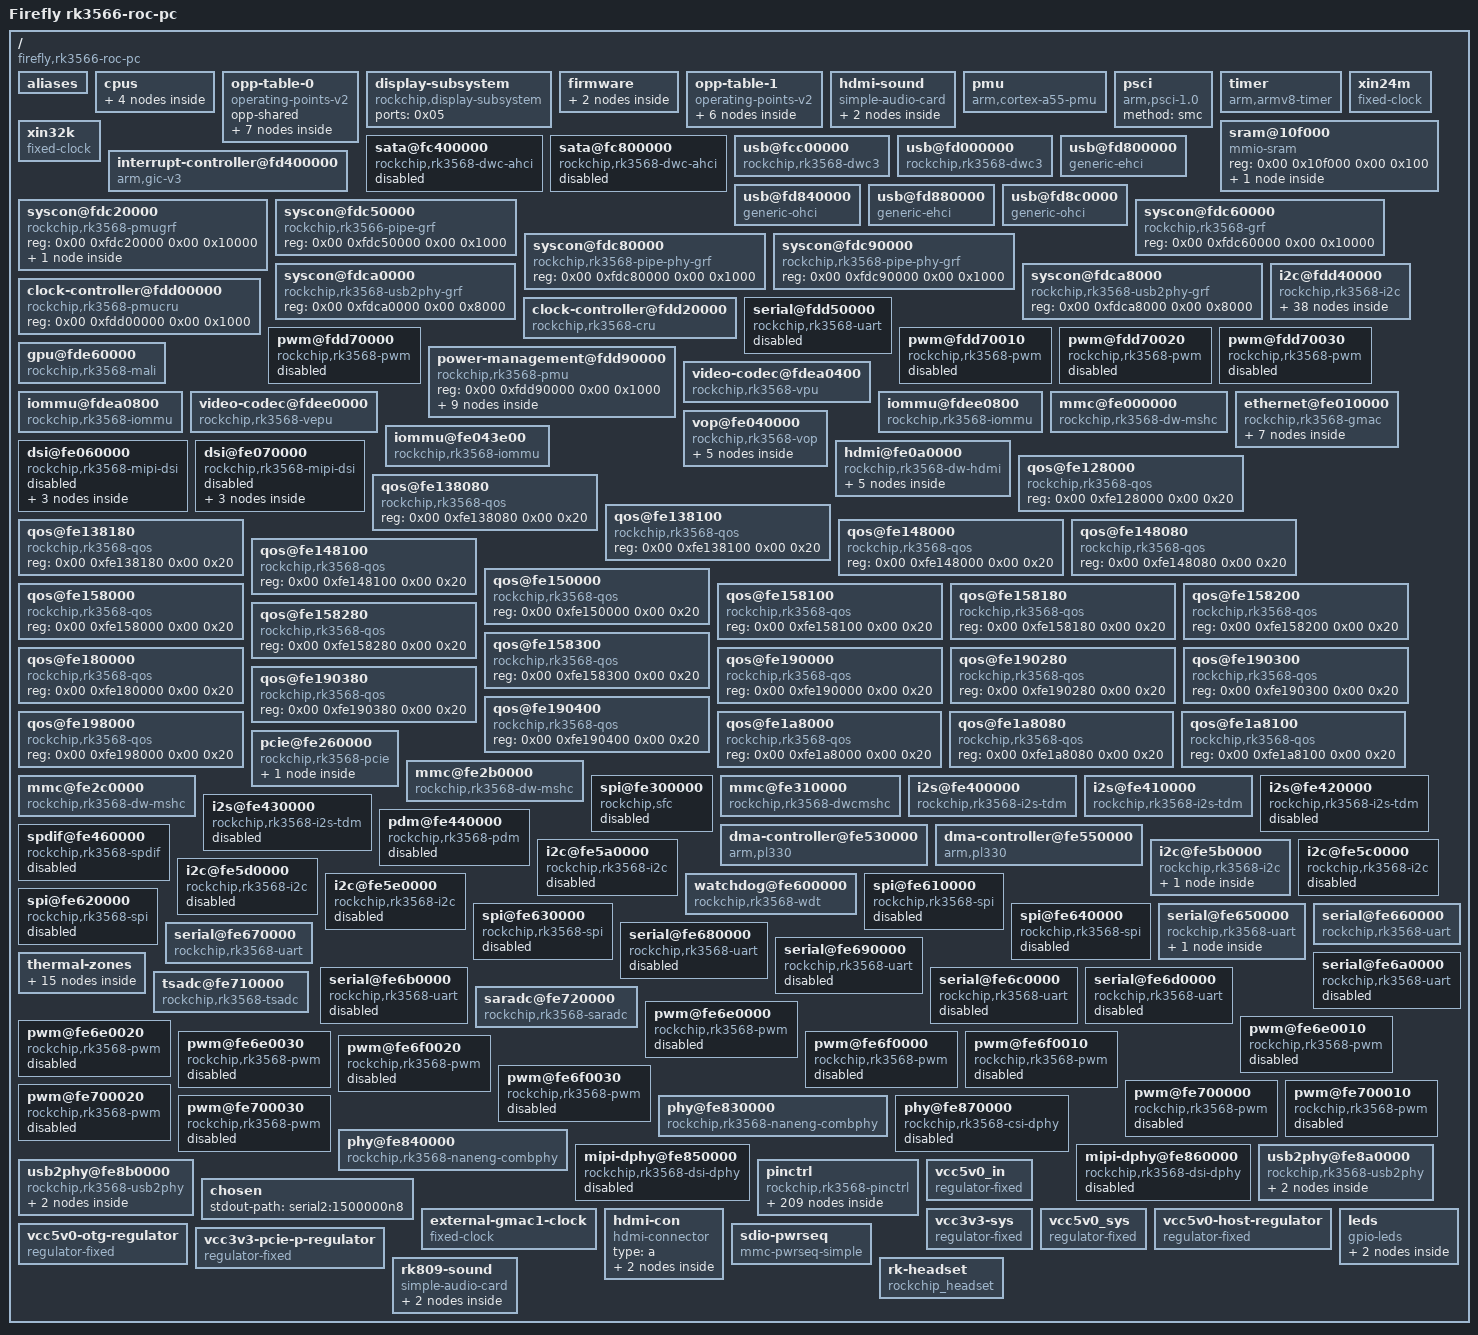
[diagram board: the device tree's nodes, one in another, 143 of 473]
/dts-v1/;

/ {
	interrupt-parent = <0x01>;
	#address-cells = <0x02>;
	#size-cells = <0x02>;
	compatible = "firefly,rk3566-roc-pc\0rockchip,rk3566";
	model = "Firefly rk3566-roc-pc";

	aliases {
		gpio0 = "/pinctrl/gpio@fdd60000";
		gpio1 = "/pinctrl/gpio@fe740000";
		gpio2 = "/pinctrl/gpio@fe750000";
		gpio3 = "/pinctrl/gpio@fe760000";
		gpio4 = "/pinctrl/gpio@fe770000";
		i2c0 = "/i2c@fdd40000";
		i2c1 = "/i2c@fe5a0000";
		i2c2 = "/i2c@fe5b0000";
		i2c3 = "/i2c@fe5c0000";
		i2c4 = "/i2c@fe5d0000";
		i2c5 = "/i2c@fe5e0000";
		serial0 = "/serial@fdd50000";
		serial1 = "/serial@fe650000";
		serial2 = "/serial@fe660000";
		serial3 = "/serial@fe670000";
		serial4 = "/serial@fe680000";
		serial5 = "/serial@fe690000";
		serial6 = "/serial@fe6a0000";
		serial7 = "/serial@fe6b0000";
		serial8 = "/serial@fe6c0000";
		serial9 = "/serial@fe6d0000";
		spi0 = "/spi@fe610000";
		spi1 = "/spi@fe620000";
		spi2 = "/spi@fe630000";
		spi3 = "/spi@fe640000";
		ethernet0 = "/ethernet@fe010000";
		mmc0 = "/mmc@fe2b0000";
		mmc1 = "/mmc@fe310000";
		mmc2 = "/mmc@fe2c0000";
	};

	cpus {
		#address-cells = <0x02>;
		#size-cells = <0x00>;

		cpu@0 {
			device_type = "cpu";
			compatible = "arm,cortex-a55";
			reg = <0x00 0x00>;
			clocks = <0x02 0x00>;
			#cooling-cells = <0x02>;
			enable-method = "psci";
			operating-points-v2 = <0x03>;
			cpu-supply = <0x04>;
			phandle = <0x09>;
		};

		cpu@100 {
			device_type = "cpu";
			compatible = "arm,cortex-a55";
			reg = <0x00 0x100>;
			#cooling-cells = <0x02>;
			enable-method = "psci";
			operating-points-v2 = <0x03>;
			cpu-supply = <0x04>;
			phandle = <0x0a>;
		};

		cpu@200 {
			device_type = "cpu";
			compatible = "arm,cortex-a55";
			reg = <0x00 0x200>;
			#cooling-cells = <0x02>;
			enable-method = "psci";
			operating-points-v2 = <0x03>;
			cpu-supply = <0x04>;
			phandle = <0x0b>;
		};

		cpu@300 {
			device_type = "cpu";
			compatible = "arm,cortex-a55";
			reg = <0x00 0x300>;
			#cooling-cells = <0x02>;
			enable-method = "psci";
			operating-points-v2 = <0x03>;
			cpu-supply = <0x04>;
			phandle = <0x0c>;
		};
	};

	opp-table-0 {
		compatible = "operating-points-v2";
		opp-shared;
		phandle = <0x03>;

		opp-408000000 {
			opp-hz = <0x00 0x18519600>;
			opp-microvolt = <0xdbba0 0xdbba0 0x118c30>;
			clock-latency-ns = <0x9c40>;
		};

		opp-600000000 {
			opp-hz = <0x00 0x23c34600>;
			opp-microvolt = <0xdbba0 0xdbba0 0x118c30>;
		};

		opp-816000000 {
			opp-hz = <0x00 0x30a32c00>;
			opp-microvolt = <0xdbba0 0xdbba0 0x118c30>;
			opp-suspend;
		};

		opp-1104000000 {
			opp-hz = <0x00 0x41cdb400>;
			opp-microvolt = <0xdbba0 0xdbba0 0x118c30>;
		};

		opp-1416000000 {
			opp-hz = <0x00 0x54667200>;
			opp-microvolt = <0xdbba0 0xdbba0 0x118c30>;
		};

		opp-1608000000 {
			opp-hz = <0x00 0x5fd82200>;
			opp-microvolt = <0xee098 0xee098 0x118c30>;
		};

		opp-1800000000 {
			opp-hz = <0x00 0x6b49d200>;
			opp-microvolt = <0x100590 0x100590 0x118c30>;
		};
	};

	display-subsystem {
		compatible = "rockchip,display-subsystem";
		ports = <0x05>;
	};

	firmware {

		scmi {
			compatible = "arm,scmi-smc";
			arm,smc-id = <0x82000010>;
			shmem = <0x06>;
			#address-cells = <0x01>;
			#size-cells = <0x00>;

			protocol@14 {
				reg = <0x14>;
				#clock-cells = <0x01>;
				phandle = <0x02>;
			};
		};
	};

	opp-table-1 {
		compatible = "operating-points-v2";
		phandle = <0x42>;

		opp-200000000 {
			opp-hz = <0x00 0xbebc200>;
			opp-microvolt = <0xc96a8>;
		};

		opp-300000000 {
			opp-hz = <0x00 0x11e1a300>;
			opp-microvolt = <0xc96a8>;
		};

		opp-400000000 {
			opp-hz = <0x00 0x17d78400>;
			opp-microvolt = <0xc96a8>;
		};

		opp-600000000 {
			opp-hz = <0x00 0x23c34600>;
			opp-microvolt = <0xc96a8>;
		};

		opp-700000000 {
			opp-hz = <0x00 0x29b92700>;
			opp-microvolt = <0xdbba0>;
		};

		opp-800000000 {
			opp-hz = <0x00 0x2faf0800>;
			opp-microvolt = <0xf4240>;
		};
	};

	hdmi-sound {
		compatible = "simple-audio-card";
		simple-audio-card,name = "HDMI";
		simple-audio-card,format = "i2s";
		simple-audio-card,mclk-fs = <0x100>;
		status = "okay";

		simple-audio-card,codec {
			sound-dai = <0x07>;
		};

		simple-audio-card,cpu {
			sound-dai = <0x08>;
		};
	};

	pmu {
		compatible = "arm,cortex-a55-pmu";
		interrupts = <0x00 0xe4 0x04 0x00 0xe5 0x04 0x00 0xe6 0x04 0x00 0xe7 0x04>;
		interrupt-affinity = <0x09 0x0a 0x0b 0x0c>;
	};

	psci {
		compatible = "arm,psci-1.0";
		method = "smc";
	};

	timer {
		compatible = "arm,armv8-timer";
		interrupts = <0x01 0x0d 0x04 0x01 0x0e 0x04 0x01 0x0b 0x04 0x01 0x0a 0x04>;
		arm,no-tick-in-suspend;
	};

	xin24m {
		compatible = "fixed-clock";
		clock-frequency = <0x16e3600>;
		clock-output-names = "xin24m";
		#clock-cells = <0x00>;
		phandle = <0x1c>;
	};

	xin32k {
		compatible = "fixed-clock";
		clock-frequency = <0x8000>;
		clock-output-names = "xin32k";
		pinctrl-0 = <0x0d>;
		pinctrl-names = "default";
		#clock-cells = <0x00>;
	};

	sram@10f000 {
		compatible = "mmio-sram";
		reg = <0x00 0x10f000 0x00 0x100>;
		#address-cells = <0x01>;
		#size-cells = <0x01>;
		ranges = <0x00 0x00 0x10f000 0x100>;

		sram@0 {
			compatible = "arm,scmi-shmem";
			reg = <0x00 0x100>;
			phandle = <0x06>;
		};
	};

	sata@fc400000 {
		compatible = "rockchip,rk3568-dwc-ahci\0snps,dwc-ahci";
		reg = <0x00 0xfc400000 0x00 0x1000>;
		clocks = <0x0e 0x9b 0x0e 0x9c 0x0e 0x9d>;
		clock-names = "sata\0pmalive\0rxoob";
		interrupts = <0x00 0x5f 0x04>;
		phys = <0x0f 0x01>;
		phy-names = "sata-phy";
		ports-implemented = <0x01>;
		power-domains = <0x10 0x0f>;
		status = "disabled";
	};

	sata@fc800000 {
		compatible = "rockchip,rk3568-dwc-ahci\0snps,dwc-ahci";
		reg = <0x00 0xfc800000 0x00 0x1000>;
		clocks = <0x0e 0xa0 0x0e 0xa1 0x0e 0xa2>;
		clock-names = "sata\0pmalive\0rxoob";
		interrupts = <0x00 0x60 0x04>;
		phys = <0x11 0x01>;
		phy-names = "sata-phy";
		ports-implemented = <0x01>;
		power-domains = <0x10 0x0f>;
		status = "disabled";
	};

	usb@fcc00000 {
		compatible = "rockchip,rk3568-dwc3\0snps,dwc3";
		reg = <0x00 0xfcc00000 0x00 0x400000>;
		interrupts = <0x00 0xa9 0x04>;
		clocks = <0x0e 0xa6 0x0e 0xa7 0x0e 0xa5>;
		clock-names = "ref_clk\0suspend_clk\0bus_clk";
		dr_mode = "host";
		phy_type = "utmi_wide";
		power-domains = <0x10 0x0f>;
		resets = <0x0e 0x94>;
		snps,dis_u2_susphy_quirk;
		status = "okay";
		phys = <0x12>;
		phy-names = "usb2-phy";
		extcon = <0x13>;
		maximum-speed = "high-speed";
	};

	usb@fd000000 {
		compatible = "rockchip,rk3568-dwc3\0snps,dwc3";
		reg = <0x00 0xfd000000 0x00 0x400000>;
		interrupts = <0x00 0xaa 0x04>;
		clocks = <0x0e 0xa9 0x0e 0xaa 0x0e 0xa8>;
		clock-names = "ref_clk\0suspend_clk\0bus_clk";
		dr_mode = "host";
		phys = <0x14 0x0f 0x04>;
		phy-names = "usb2-phy\0usb3-phy";
		phy_type = "utmi_wide";
		power-domains = <0x10 0x0f>;
		resets = <0x0e 0x95>;
		snps,dis_u2_susphy_quirk;
		status = "okay";
	};

	interrupt-controller@fd400000 {
		compatible = "arm,gic-v3";
		reg = <0x00 0xfd400000 0x00 0x10000 0x00 0xfd460000 0x00 0x80000>;
		interrupts = <0x01 0x09 0x04>;
		interrupt-controller;
		#interrupt-cells = <0x03>;
		mbi-alias = <0x00 0xfd410000>;
		mbi-ranges = <0x128 0x18>;
		msi-controller;
		phandle = <0x01>;
	};

	usb@fd800000 {
		compatible = "generic-ehci";
		reg = <0x00 0xfd800000 0x00 0x40000>;
		interrupts = <0x00 0x82 0x04>;
		clocks = <0x0e 0xbd 0x0e 0xbe 0x0e 0xbc>;
		phys = <0x15>;
		phy-names = "usb";
		status = "okay";
	};

	usb@fd840000 {
		compatible = "generic-ohci";
		reg = <0x00 0xfd840000 0x00 0x40000>;
		interrupts = <0x00 0x83 0x04>;
		clocks = <0x0e 0xbd 0x0e 0xbe 0x0e 0xbc>;
		phys = <0x15>;
		phy-names = "usb";
		status = "okay";
	};

	usb@fd880000 {
		compatible = "generic-ehci";
		reg = <0x00 0xfd880000 0x00 0x40000>;
		interrupts = <0x00 0x85 0x04>;
		clocks = <0x0e 0xbf 0x0e 0xc0 0x0e 0xbc>;
		phys = <0x16>;
		phy-names = "usb";
		status = "okay";
	};

	usb@fd8c0000 {
		compatible = "generic-ohci";
		reg = <0x00 0xfd8c0000 0x00 0x40000>;
		interrupts = <0x00 0x86 0x04>;
		clocks = <0x0e 0xbf 0x0e 0xc0 0x0e 0xbc>;
		phys = <0x16>;
		phy-names = "usb";
		status = "okay";
	};

	syscon@fdc20000 {
		compatible = "rockchip,rk3568-pmugrf\0syscon\0simple-mfd";
		reg = <0x00 0xfdc20000 0x00 0x10000>;
		phandle = <0xbb>;

		io-domains {
			compatible = "rockchip,rk3568-pmu-io-voltage-domain";
			status = "okay";
			pmuio1-supply = <0x17>;
			pmuio2-supply = <0x17>;
			vccio1-supply = <0x18>;
			vccio2-supply = <0x19>;
			vccio3-supply = <0x1a>;
			vccio4-supply = <0x19>;
			vccio5-supply = <0x1b>;
			vccio6-supply = <0x19>;
			vccio7-supply = <0x1b>;
		};
	};

	syscon@fdc50000 {
		reg = <0x00 0xfdc50000 0x00 0x1000>;
		compatible = "rockchip,rk3566-pipe-grf\0syscon";
		phandle = <0xb4>;
	};

	syscon@fdc60000 {
		compatible = "rockchip,rk3568-grf\0syscon\0simple-mfd";
		reg = <0x00 0xfdc60000 0x00 0x10000>;
		phandle = <0x1e>;
	};

	syscon@fdc80000 {
		compatible = "rockchip,rk3568-pipe-phy-grf\0syscon";
		reg = <0x00 0xfdc80000 0x00 0x1000>;
		phandle = <0xb5>;
	};

	syscon@fdc90000 {
		compatible = "rockchip,rk3568-pipe-phy-grf\0syscon";
		reg = <0x00 0xfdc90000 0x00 0x1000>;
		phandle = <0xb6>;
	};

	syscon@fdca0000 {
		compatible = "rockchip,rk3568-usb2phy-grf\0syscon";
		reg = <0x00 0xfdca0000 0x00 0x8000>;
		phandle = <0xb7>;
	};

	syscon@fdca8000 {
		compatible = "rockchip,rk3568-usb2phy-grf\0syscon";
		reg = <0x00 0xfdca8000 0x00 0x8000>;
		phandle = <0xba>;
	};

	clock-controller@fdd00000 {
		compatible = "rockchip,rk3568-pmucru";
		reg = <0x00 0xfdd00000 0x00 0x1000>;
		#clock-cells = <0x01>;
		#reset-cells = <0x01>;
		phandle = <0x1d>;
	};

	clock-controller@fdd20000 {
		compatible = "rockchip,rk3568-cru";
		reg = <0x00 0xfdd20000 0x00 0x1000>;
		clocks = <0x1c>;
		clock-names = "xin24m";
		#clock-cells = <0x01>;
		#reset-cells = <0x01>;
		assigned-clocks = <0x1d 0x05 0x0e 0x04 0x1d 0x01>;
		assigned-clock-rates = <0x8000 0x47868c00 0xbebc200>;
		assigned-clock-parents = <0x1d 0x08>;
		rockchip,grf = <0x1e>;
		phandle = <0x0e>;
	};

	i2c@fdd40000 {
		compatible = "rockchip,rk3568-i2c\0rockchip,rk3399-i2c";
		reg = <0x00 0xfdd40000 0x00 0x1000>;
		interrupts = <0x00 0x2e 0x04>;
		clocks = <0x1d 0x07 0x1d 0x2d>;
		clock-names = "i2c\0pclk";
		pinctrl-0 = <0x1f>;
		pinctrl-names = "default";
		#address-cells = <0x01>;
		#size-cells = <0x00>;
		status = "okay";

		regulator@1c {
			compatible = "tcs,tcs4525";
			reg = <0x1c>;
			vin-supply = <0x20>;
			regulator-name = "vdd_cpu";
			regulator-min-microvolt = "\0\f5";
			regulator-max-microvolt = <0x118c30>;
			regulator-ramp-delay = <0x8fc>;
			fcs,suspend-voltage-selector = <0x01>;
			regulator-boot-on;
			regulator-always-on;
			phandle = <0x04>;

			regulator-state-mem {
				regulator-off-in-suspend;
			};
		};

		pmic@20 {
			compatible = "rockchip,rk809";
			reg = <0x20>;
			interrupt-parent = <0x21>;
			interrupts = <0x07 0x08>;
			clock-output-names = "rk808-clkout1\0rk808-clkout2";
			assigned-clocks = <0x0e 0x48>;
			assigned-clock-parents = <0x0e 0x196>;
			clock-names = "mclk";
			clocks = <0x0e 0x48>;
			pinctrl-names = "default";
			pinctrl-0 = <0x22 0x23>;
			rockchip,system-power-controller;
			wakeup-source;
			#clock-cells = <0x01>;
			#sound-dai-cells = <0x00>;
			vcc1-supply = <0x24>;
			vcc2-supply = <0x24>;
			vcc3-supply = <0x24>;
			vcc4-supply = <0x24>;
			vcc5-supply = <0x24>;
			vcc6-supply = <0x24>;
			vcc7-supply = <0x24>;
			vcc8-supply = <0x24>;
			vcc9-supply = <0x24>;
			phandle = <0x94>;

			regulators {

				DCDC_REG1 {
					regulator-name = "vdd_logic";
					regulator-always-on;
					regulator-boot-on;
					regulator-init-microvolt = <0xdbba0>;
					regulator-initial-mode = <0x02>;
					regulator-min-microvolt = <0x7a120>;
					regulator-max-microvolt = <0x149970>;
					regulator-ramp-delay = <0x1771>;

					regulator-state-mem {
						regulator-off-in-suspend;
					};
				};

				DCDC_REG2 {
					regulator-always-on;
					regulator-boot-on;
					regulator-name = "vdd_gpu";
					regulator-init-microvolt = <0xdbba0>;
					regulator-initial-mode = <0x02>;
					regulator-min-microvolt = <0x7a120>;
					regulator-max-microvolt = <0x149970>;
					regulator-ramp-delay = <0x1771>;
					phandle = <0x43>;

					regulator-state-mem {
						regulator-off-in-suspend;
					};
				};

				DCDC_REG3 {
					regulator-name = "vcc_ddr";
					regulator-always-on;
					regulator-boot-on;
					regulator-initial-mode = <0x02>;

					regulator-state-mem {
						regulator-on-in-suspend;
					};
				};

				DCDC_REG4 {
					regulator-name = "vdd_npu";
					regulator-init-microvolt = <0xdbba0>;
					regulator-initial-mode = <0x02>;
					regulator-min-microvolt = <0x7a120>;
					regulator-max-microvolt = <0x149970>;
					regulator-ramp-delay = <0x1771>;

					regulator-state-mem {
						regulator-off-in-suspend;
					};
				};

				LDO_REG1 {
					regulator-boot-on;
					regulator-always-on;
					regulator-name = "vdda0v9_image";
					regulator-min-microvolt = <0xdbba0>;
					regulator-max-microvolt = <0xdbba0>;
					phandle = <0x5c>;

					regulator-state-mem {
						regulator-off-in-suspend;
					};
				};

				LDO_REG2 {
					regulator-name = "vdda_0v9";
					regulator-always-on;
					regulator-boot-on;
					regulator-min-microvolt = <0xdbba0>;
					regulator-max-microvolt = <0xdbba0>;

					regulator-state-mem {
						regulator-off-in-suspend;
					};
				};

				LDO_REG3 {
					regulator-name = "vdda0v9_pmu";
					regulator-always-on;
					regulator-boot-on;
					regulator-min-microvolt = <0xdbba0>;
					regulator-max-microvolt = <0xdbba0>;

					regulator-state-mem {
						regulator-on-in-suspend;
						regulator-suspend-microvolt = <0xdbba0>;
					};
				};

				LDO_REG4 {
					regulator-always-on;
					regulator-boot-on;
					regulator-name = "vccio_acodec";
					regulator-min-microvolt = <0x325aa0>;
					regulator-max-microvolt = <0x325aa0>;
					phandle = <0x18>;

					regulator-state-mem {
						regulator-off-in-suspend;
					};
				};

				LDO_REG5 {
					regulator-name = "vccio_sd";
					regulator-always-on;
					regulator-boot-on;
					regulator-min-microvolt = <0x1b7740>;
					regulator-max-microvolt = <0x325aa0>;
					phandle = <0x1a>;

					regulator-state-mem {
						regulator-off-in-suspend;
					};
				};

				LDO_REG6 {
					regulator-name = "vcc3v3_pmu";
					regulator-always-on;
					regulator-boot-on;
					regulator-min-microvolt = <0x325aa0>;
					regulator-max-microvolt = <0x325aa0>;
					phandle = <0x17>;

					regulator-state-mem {
						regulator-on-in-suspend;
						regulator-suspend-microvolt = <0x325aa0>;
					};
				};

				LDO_REG7 {
					regulator-name = "vcca_1v8";
					regulator-always-on;
					regulator-boot-on;
					regulator-min-microvolt = <0x1b7740>;
					regulator-max-microvolt = <0x1b7740>;
					phandle = <0xa7>;

					regulator-state-mem {
						regulator-off-in-suspend;
					};
				};

				LDO_REG8 {
					regulator-name = "vcca1v8_pmu";
					regulator-always-on;
					regulator-boot-on;
					regulator-min-microvolt = <0x1b7740>;
					regulator-max-microvolt = <0x1b7740>;
					phandle = <0x46>;

					regulator-state-mem {
						regulator-on-in-suspend;
						regulator-suspend-microvolt = <0x1b7740>;
					};
				};

				LDO_REG9 {
					regulator-name = "vcca1v8_image";
					regulator-min-microvolt = <0x1b7740>;
					regulator-max-microvolt = <0x1b7740>;
					phandle = <0x5d>;

					regulator-state-mem {
						regulator-off-in-suspend;
					};
				};

				DCDC_REG5 {
					regulator-always-on;
					regulator-boot-on;
					regulator-min-microvolt = <0x1b7740>;
					regulator-max-microvolt = <0x1b7740>;
					regulator-name = "vcc_1v8";
					phandle = <0x19>;

					regulator-state-mem {
						regulator-off-in-suspend;
					};
				};

				SWITCH_REG1 {
					regulator-name = "vcc_3v3";
					regulator-always-on;
					regulator-boot-on;
					phandle = <0x1b>;

					regulator-state-mem {
						regulator-off-in-suspend;
					};
				};

				SWITCH_REG2 {
					regulator-name = "vcc3v3_sd";
					regulator-always-on;
					regulator-boot-on;
					phandle = <0x68>;

					regulator-state-mem {
						regulator-off-in-suspend;
					};
				};
			};

			rtc {
				status = "disabled";
			};

			codec {
				mic-in-differential;
			};
		};
	};

	serial@fdd50000 {
		compatible = "rockchip,rk3568-uart\0snps,dw-apb-uart";
		reg = <0x00 0xfdd50000 0x00 0x100>;
		interrupts = <0x00 0x74 0x04>;
		clocks = <0x1d 0x0b 0x1d 0x2c>;
		clock-names = "baudclk\0apb_pclk";
		dmas = <0x25 0x00 0x25 0x01>;
		pinctrl-0 = <0x26>;
		pinctrl-names = "default";
		reg-io-width = <0x04>;
		reg-shift = <0x02>;
		status = "disabled";
	};

	pwm@fdd70000 {
		compatible = "rockchip,rk3568-pwm\0rockchip,rk3328-pwm";
		reg = <0x00 0xfdd70000 0x00 0x10>;
		clocks = <0x1d 0x0d 0x1d 0x30>;
		clock-names = "pwm\0pclk";
		pinctrl-0 = <0x27>;
		pinctrl-names = "default";
		#pwm-cells = <0x03>;
		status = "disabled";
	};

	pwm@fdd70010 {
		compatible = "rockchip,rk3568-pwm\0rockchip,rk3328-pwm";
		reg = <0x00 0xfdd70010 0x00 0x10>;
		clocks = <0x1d 0x0d 0x1d 0x30>;
		clock-names = "pwm\0pclk";
		pinctrl-0 = <0x28>;
		pinctrl-names = "default";
		#pwm-cells = <0x03>;
		status = "disabled";
	};

	pwm@fdd70020 {
		compatible = "rockchip,rk3568-pwm\0rockchip,rk3328-pwm";
		reg = <0x00 0xfdd70020 0x00 0x10>;
		clocks = <0x1d 0x0d 0x1d 0x30>;
		clock-names = "pwm\0pclk";
		pinctrl-0 = <0x29>;
		pinctrl-names = "default";
		#pwm-cells = <0x03>;
		status = "disabled";
	};

	pwm@fdd70030 {
		compatible = "rockchip,rk3568-pwm\0rockchip,rk3328-pwm";
		reg = <0x00 0xfdd70030 0x00 0x10>;
		clocks = <0x1d 0x0d 0x1d 0x30>;
		clock-names = "pwm\0pclk";
		pinctrl-0 = <0x2a>;
		pinctrl-names = "default";
		#pwm-cells = <0x03>;
		status = "disabled";
	};

	power-management@fdd90000 {
		compatible = "rockchip,rk3568-pmu\0syscon\0simple-mfd";
		reg = <0x00 0xfdd90000 0x00 0x1000>;

		power-controller {
			compatible = "rockchip,rk3568-power-controller";
			#power-domain-cells = <0x01>;
			#address-cells = <0x01>;
			#size-cells = <0x00>;
			phandle = <0x10>;

			power-domain@7 {
				reg = <0x07>;
				clocks = <0x0e 0x19 0x0e 0x1a>;
				pm_qos = <0x2b>;
				#power-domain-cells = <0x00>;
			};

			power-domain@8 {
				reg = <0x08>;
				clocks = <0x0e 0xcc 0x0e 0xcd>;
				pm_qos = <0x2c 0x2d 0x2e>;
				#power-domain-cells = <0x00>;
			};

			power-domain@9 {
				reg = <0x09>;
				clocks = <0x0e 0xda 0x0e 0xdb 0x0e 0xdc>;
				pm_qos = <0x2f 0x30 0x31>;
				#power-domain-cells = <0x00>;
			};

			power-domain@10 {
				reg = <0x0a>;
				clocks = <0x0e 0xf1 0x0e 0xf2>;
				pm_qos = <0x32 0x33 0x34 0x35 0x36 0x37>;
				#power-domain-cells = <0x00>;
			};

			power-domain@11 {
				reg = <0x0b>;
				clocks = <0x0e 0xed>;
				pm_qos = <0x38>;
				#power-domain-cells = <0x00>;
			};

			power-domain@13 {
				clocks = <0x0e 0x107>;
				reg = <0x0d>;
				pm_qos = <0x39>;
				#power-domain-cells = <0x00>;
			};

			power-domain@14 {
				reg = <0x0e>;
				clocks = <0x0e 0x102>;
				pm_qos = <0x3a 0x3b 0x3c>;
				#power-domain-cells = <0x00>;
			};

			power-domain@15 {
				reg = <0x0f>;
				clocks = <0x0e 0x7f>;
				pm_qos = <0x3d 0x3e 0x3f 0x40 0x41>;
				#power-domain-cells = <0x00>;
			};
		};
	};

	gpu@fde60000 {
		compatible = "rockchip,rk3568-mali\0arm,mali-bifrost";
		reg = <0x00 0xfde60000 0x00 0x4000>;
		interrupts = <0x00 0x28 0x04 0x00 0x29 0x04 0x00 0x27 0x04>;
		interrupt-names = "job\0mmu\0gpu";
		clocks = <0x02 0x01 0x0e 0x1b>;
		clock-names = "gpu\0bus";
		#cooling-cells = <0x02>;
		operating-points-v2 = <0x42>;
		power-domains = <0x10 0x07>;
		status = "okay";
		mali-supply = <0x43>;
		phandle = <0xa4>;
	};

	video-codec@fdea0400 {
		compatible = "rockchip,rk3568-vpu";
		reg = <0x00 0xfdea0000 0x00 0x800>;
		interrupts = <0x00 0x8b 0x04>;
		clocks = <0x0e 0xee 0x0e 0xef>;
		clock-names = "aclk\0hclk";
		iommus = <0x44>;
		power-domains = <0x10 0x0b>;
	};

	iommu@fdea0800 {
		compatible = "rockchip,rk3568-iommu";
		reg = <0x00 0xfdea0800 0x00 0x40>;
		interrupts = <0x00 0x8a 0x04>;
		clock-names = "aclk\0iface";
		clocks = <0x0e 0xee 0x0e 0xef>;
		power-domains = <0x10 0x0b>;
		#iommu-cells = <0x00>;
		phandle = <0x44>;
	};

	video-codec@fdee0000 {
		compatible = "rockchip,rk3568-vepu";
		reg = <0x00 0xfdee0000 0x00 0x800>;
		interrupts = <0x00 0x40 0x04>;
		clocks = <0x0e 0xfd 0x0e 0xfe>;
		clock-names = "aclk\0hclk";
		iommus = <0x45>;
		power-domains = <0x10 0x0a>;
	};

	iommu@fdee0800 {
		compatible = "rockchip,rk3568-iommu";
		reg = <0x00 0xfdee0800 0x00 0x40>;
		interrupts = <0x00 0x3f 0x04>;
		clocks = <0x0e 0xfd 0x0e 0xfe>;
		clock-names = "aclk\0iface";
		power-domains = <0x10 0x0a>;
		#iommu-cells = <0x00>;
		phandle = <0x45>;
	};

	mmc@fe000000 {
		compatible = "rockchip,rk3568-dw-mshc\0rockchip,rk3288-dw-mshc";
		reg = <0x00 0xfe000000 0x00 0x4000>;
		interrupts = <0x00 0x64 0x04>;
		clocks = <0x0e 0xc1 0x0e 0xc2 0x0e 0x18e 0x0e 0x18f>;
		clock-names = "biu\0ciu\0ciu-drive\0ciu-sample";
		fifo-depth = <0x100>;
		max-frequency = <0x8f0d180>;
		resets = <0x0e 0xeb>;
		reset-names = "reset";
		status = "okay";
		cap-sd-highspeed;
		cap-sdio-irq;
		bus-width = <0x04>;
		vmmc-supply = <0x1b>;
		vqmmc-supply = <0x46>;
		pinctrl-names = "default";
		pinctrl-0 = <0x47 0x48 0x49>;
		sd-uhs-sdr104;
	};

	ethernet@fe010000 {
		compatible = "rockchip,rk3568-gmac\0snps,dwmac-4.20a";
		reg = <0x00 0xfe010000 0x00 0x10000>;
		interrupts = <0x00 0x20 0x04 0x00 0x1d 0x04>;
		interrupt-names = "macirq\0eth_wake_irq";
		clocks = <0x0e 0x186 0x0e 0x189 0x0e 0x189 0x0e 0xc7 0x0e 0xc3 0x0e 0xc4 0x0e 0x189 0x0e 0xc8>;
		clock-names = "stmmaceth\0mac_clk_rx\0mac_clk_tx\0clk_mac_refout\0aclk_mac\0pclk_mac\0clk_mac_speed\0ptp_ref";
		resets = <0x0e 0xec>;
		reset-names = "stmmaceth";
		rockchip,grf = <0x1e>;
		snps,axi-config = <0x4a>;
		snps,mixed-burst;
		snps,mtl-rx-config = <0x4b>;
		snps,mtl-tx-config = <0x4c>;
		snps,tso;
		status = "okay";
		assigned-clocks = <0x0e 0x189 0x0e 0x187 0x0e 0x186>;
		assigned-clock-parents = <0x0e 0x187 0x0e 0x186 0x4d>;
		clock_in_out = "input";
		phy-supply = <0x1b>;
		phy-mode = "rgmii";
		pinctrl-names = "default";
		pinctrl-0 = <0x4e 0x4f 0x50 0x51 0x52 0x53>;
		snps,reset-gpio = <0x21 0x0f 0x01>;
		snps,reset-active-low;
		snps,reset-delays-us = <0x00 0x4e20 0x186a0>;
		tx_delay = <0x4e>;
		rx_delay = <0x2c>;
		phy-handle = <0x54>;

		mdio {
			compatible = "snps,dwmac-mdio";
			#address-cells = <0x01>;
			#size-cells = <0x00>;

			ethernet-phy@0 {
				compatible = "ethernet-phy-ieee802.3-c22";
				reg = <0x00>;
				phandle = <0x54>;
			};
		};

		stmmac-axi-config {
			snps,blen = <0x00 0x00 0x00 0x00 0x10 0x08 0x04>;
			snps,rd_osr_lmt = <0x08>;
			snps,wr_osr_lmt = <0x04>;
			phandle = <0x4a>;
		};

		rx-queues-config {
			snps,rx-queues-to-use = <0x01>;
			phandle = <0x4b>;

			queue0 {
			};
		};

		tx-queues-config {
			snps,tx-queues-to-use = <0x01>;
			phandle = <0x4c>;

			queue0 {
			};
		};
	};

	vop@fe040000 {
		reg = <0x00 0xfe040000 0x00 0x3000 0x00 0xfe044000 0x00 0x1000>;
		reg-names = "vop\0gamma-lut";
		interrupts = <0x00 0x94 0x04>;
		clocks = <0x0e 0xdd 0x0e 0xde 0x0e 0xdf 0x0e 0xe0 0x0e 0xe1>;
		clock-names = "aclk\0hclk\0dclk_vp0\0dclk_vp1\0dclk_vp2";
		iommus = <0x55>;
		power-domains = <0x10 0x09>;
		rockchip,grf = <0x1e>;
		status = "okay";
		compatible = "rockchip,rk3568-vop";
		assigned-clocks = <0x0e 0xdf 0x0e 0xe0>;
		assigned-clock-parents = <0x1d 0x02 0x0e 0x05>;

		ports {
			#address-cells = <0x01>;
			#size-cells = <0x00>;
			phandle = <0x05>;

			port@0 {
				reg = <0x00>;
				#address-cells = <0x01>;
				#size-cells = <0x00>;

				endpoint@2 {
					reg = <0x02>;
					remote-endpoint = <0x56>;
					phandle = <0x5e>;
				};
			};

			port@1 {
				reg = <0x01>;
				#address-cells = <0x01>;
				#size-cells = <0x00>;
			};

			port@2 {
				reg = <0x02>;
				#address-cells = <0x01>;
				#size-cells = <0x00>;
			};
		};
	};

	iommu@fe043e00 {
		compatible = "rockchip,rk3568-iommu";
		reg = <0x00 0xfe043e00 0x00 0x100 0x00 0xfe043f00 0x00 0x100>;
		interrupts = <0x00 0x94 0x04>;
		clocks = <0x0e 0xdd 0x0e 0xde>;
		clock-names = "aclk\0iface";
		#iommu-cells = <0x00>;
		status = "okay";
		phandle = <0x55>;
	};

	dsi@fe060000 {
		compatible = "rockchip,rk3568-mipi-dsi\0snps,dw-mipi-dsi";
		reg = <0x00 0xfe060000 0x00 0x10000>;
		interrupts = <0x00 0x44 0x04>;
		clock-names = "pclk";
		clocks = <0x0e 0xe8>;
		phy-names = "dphy";
		phys = <0x57>;
		power-domains = <0x10 0x09>;
		reset-names = "apb";
		resets = <0x0e 0x110>;
		rockchip,grf = <0x1e>;
		status = "disabled";

		ports {
			#address-cells = <0x01>;
			#size-cells = <0x00>;

			port@0 {
				reg = <0x00>;
			};

			port@1 {
				reg = <0x01>;
			};
		};
	};

	dsi@fe070000 {
		compatible = "rockchip,rk3568-mipi-dsi\0snps,dw-mipi-dsi";
		reg = <0x00 0xfe070000 0x00 0x10000>;
		interrupts = <0x00 0x45 0x04>;
		clock-names = "pclk";
		clocks = <0x0e 0xe9>;
		phy-names = "dphy";
		phys = <0x58>;
		power-domains = <0x10 0x09>;
		reset-names = "apb";
		resets = <0x0e 0x111>;
		rockchip,grf = <0x1e>;
		status = "disabled";

		ports {
			#address-cells = <0x01>;
			#size-cells = <0x00>;

			port@0 {
				reg = <0x00>;
			};

			port@1 {
				reg = <0x01>;
			};
		};
	};

	hdmi@fe0a0000 {
		compatible = "rockchip,rk3568-dw-hdmi";
		reg = <0x00 0xfe0a0000 0x00 0x20000>;
		interrupts = <0x00 0x2d 0x04>;
		clocks = <0x0e 0xe6 0x0e 0xe7 0x0e 0x193 0x1d 0x28 0x0e 0xda>;
		clock-names = "iahb\0isfr\0cec\0ref";
		pinctrl-names = "default";
		pinctrl-0 = <0x59 0x5a 0x5b>;
		power-domains = <0x10 0x09>;
		reg-io-width = <0x04>;
		rockchip,grf = <0x1e>;
		#sound-dai-cells = <0x00>;
		status = "okay";
		avdd-0v9-supply = <0x5c>;
		avdd-1v8-supply = <0x5d>;
		phandle = <0x07>;

		ports {
			#address-cells = <0x01>;
			#size-cells = <0x00>;

			port@0 {
				reg = <0x00>;

				endpoint@0 {
					remote-endpoint = <0x5e>;
					phandle = <0x56>;
				};
			};

			port@1 {
				reg = <0x01>;

				endpoint {
					remote-endpoint = <0x5f>;
					phandle = <0xc6>;
				};
			};
		};
	};

	qos@fe128000 {
		compatible = "rockchip,rk3568-qos\0syscon";
		reg = <0x00 0xfe128000 0x00 0x20>;
		phandle = <0x2b>;
	};

	qos@fe138080 {
		compatible = "rockchip,rk3568-qos\0syscon";
		reg = <0x00 0xfe138080 0x00 0x20>;
		phandle = <0x3a>;
	};

	qos@fe138100 {
		compatible = "rockchip,rk3568-qos\0syscon";
		reg = <0x00 0xfe138100 0x00 0x20>;
		phandle = <0x3b>;
	};

	qos@fe138180 {
		compatible = "rockchip,rk3568-qos\0syscon";
		reg = <0x00 0xfe138180 0x00 0x20>;
		phandle = <0x3c>;
	};

	qos@fe148000 {
		compatible = "rockchip,rk3568-qos\0syscon";
		reg = <0x00 0xfe148000 0x00 0x20>;
		phandle = <0x2c>;
	};

	qos@fe148080 {
		compatible = "rockchip,rk3568-qos\0syscon";
		reg = <0x00 0xfe148080 0x00 0x20>;
		phandle = <0x2d>;
	};

	qos@fe148100 {
		compatible = "rockchip,rk3568-qos\0syscon";
		reg = <0x00 0xfe148100 0x00 0x20>;
		phandle = <0x2e>;
	};

	qos@fe150000 {
		compatible = "rockchip,rk3568-qos\0syscon";
		reg = <0x00 0xfe150000 0x00 0x20>;
		phandle = <0x38>;
	};

	qos@fe158000 {
		compatible = "rockchip,rk3568-qos\0syscon";
		reg = <0x00 0xfe158000 0x00 0x20>;
		phandle = <0x32>;
	};

	qos@fe158100 {
		compatible = "rockchip,rk3568-qos\0syscon";
		reg = <0x00 0xfe158100 0x00 0x20>;
		phandle = <0x33>;
	};

	qos@fe158180 {
		compatible = "rockchip,rk3568-qos\0syscon";
		reg = <0x00 0xfe158180 0x00 0x20>;
		phandle = <0x34>;
	};

	qos@fe158200 {
		compatible = "rockchip,rk3568-qos\0syscon";
		reg = <0x00 0xfe158200 0x00 0x20>;
		phandle = <0x35>;
	};

	qos@fe158280 {
		compatible = "rockchip,rk3568-qos\0syscon";
		reg = <0x00 0xfe158280 0x00 0x20>;
		phandle = <0x36>;
	};

	qos@fe158300 {
		compatible = "rockchip,rk3568-qos\0syscon";
		reg = <0x00 0xfe158300 0x00 0x20>;
		phandle = <0x37>;
	};

	qos@fe180000 {
		compatible = "rockchip,rk3568-qos\0syscon";
		reg = <0x00 0xfe180000 0x00 0x20>;
	};

	qos@fe190000 {
		compatible = "rockchip,rk3568-qos\0syscon";
		reg = <0x00 0xfe190000 0x00 0x20>;
		phandle = <0x3d>;
	};

	qos@fe190280 {
		compatible = "rockchip,rk3568-qos\0syscon";
		reg = <0x00 0xfe190280 0x00 0x20>;
		phandle = <0x3e>;
	};

	qos@fe190300 {
		compatible = "rockchip,rk3568-qos\0syscon";
		reg = <0x00 0xfe190300 0x00 0x20>;
		phandle = <0x3f>;
	};

	qos@fe190380 {
		compatible = "rockchip,rk3568-qos\0syscon";
		reg = <0x00 0xfe190380 0x00 0x20>;
		phandle = <0x40>;
	};

	qos@fe190400 {
		compatible = "rockchip,rk3568-qos\0syscon";
		reg = <0x00 0xfe190400 0x00 0x20>;
		phandle = <0x41>;
	};

	qos@fe198000 {
		compatible = "rockchip,rk3568-qos\0syscon";
		reg = <0x00 0xfe198000 0x00 0x20>;
		phandle = <0x39>;
	};

	qos@fe1a8000 {
		compatible = "rockchip,rk3568-qos\0syscon";
		reg = <0x00 0xfe1a8000 0x00 0x20>;
		phandle = <0x2f>;
	};

	qos@fe1a8080 {
		compatible = "rockchip,rk3568-qos\0syscon";
		reg = <0x00 0xfe1a8080 0x00 0x20>;
		phandle = <0x30>;
	};

	qos@fe1a8100 {
		compatible = "rockchip,rk3568-qos\0syscon";
		reg = <0x00 0xfe1a8100 0x00 0x20>;
		phandle = <0x31>;
	};

	pcie@fe260000 {
		compatible = "rockchip,rk3568-pcie";
		reg = <0x03 0xc0000000 0x00 0x400000 0x00 0xfe260000 0x00 0x10000 0x00 0xf4000000 0x00 0x100000>;
		reg-names = "dbi\0apb\0config";
		interrupts = <0x00 0x4b 0x04 0x00 0x4a 0x04 0x00 0x49 0x04 0x00 0x48 0x04 0x00 0x47 0x04>;
		interrupt-names = "sys\0pmc\0msi\0legacy\0err";
		bus-range = <0x00 0x0f>;
		clocks = <0x0e 0x81 0x0e 0x82 0x0e 0x83 0x0e 0x84 0x0e 0x85>;
		clock-names = "aclk_mst\0aclk_slv\0aclk_dbi\0pclk\0aux";
		device_type = "pci";
		#interrupt-cells = <0x01>;
		interrupt-map-mask = <0x00 0x00 0x00 0x07>;
		interrupt-map = <0x00 0x00 0x00 0x01 0x60 0x00 0x00 0x00 0x00 0x02 0x60 0x01 0x00 0x00 0x00 0x03 0x60 0x02 0x00 0x00 0x00 0x04 0x60 0x03>;
		linux,pci-domain = <0x00>;
		num-ib-windows = <0x06>;
		num-ob-windows = <0x02>;
		max-link-speed = <0x02>;
		msi-map = <0x00 0x01 0x00 0x1000>;
		num-lanes = <0x01>;
		phys = <0x11 0x02>;
		phy-names = "pcie-phy";
		power-domains = <0x10 0x0f>;
		ranges = <0x1000000 0x00 0xf4100000 0x00 0xf4100000 0x00 0x100000 0x2000000 0x00 0xf4200000 0x00 0xf4200000 0x00 0x1e00000 0x3000000 0x00 0x40000000 0x03 0x00 0x00 0x40000000>;
		resets = <0x0e 0xa1>;
		reset-names = "pipe";
		#address-cells = <0x03>;
		#size-cells = <0x02>;
		status = "okay";
		pinctrl-names = "default";
		pinctrl-0 = <0x61>;
		reset-gpios = <0x62 0x0a 0x00>;
		vpcie3v3-supply = <0x63>;

		legacy-interrupt-controller {
			#address-cells = <0x00>;
			#interrupt-cells = <0x01>;
			interrupt-controller;
			interrupt-parent = <0x01>;
			interrupts = <0x00 0x48 0x01>;
			phandle = <0x60>;
		};
	};

	mmc@fe2b0000 {
		compatible = "rockchip,rk3568-dw-mshc\0rockchip,rk3288-dw-mshc";
		reg = <0x00 0xfe2b0000 0x00 0x4000>;
		interrupts = <0x00 0x62 0x04>;
		clocks = <0x0e 0xb0 0x0e 0xb1 0x0e 0x18a 0x0e 0x18b>;
		clock-names = "biu\0ciu\0ciu-drive\0ciu-sample";
		fifo-depth = <0x100>;
		max-frequency = <0x8f0d180>;
		resets = <0x0e 0xd4>;
		reset-names = "reset";
		status = "okay";
		bus-width = <0x04>;
		cap-sd-highspeed;
		cd-gpios = <0x21 0x04 0x01>;
		disable-wp;
		pinctrl-names = "default";
		pinctrl-0 = <0x64 0x65 0x66 0x67>;
		sd-uhs-sdr104;
		vmmc-supply = <0x68>;
		vqmmc-supply = <0x1a>;
	};

	mmc@fe2c0000 {
		compatible = "rockchip,rk3568-dw-mshc\0rockchip,rk3288-dw-mshc";
		reg = <0x00 0xfe2c0000 0x00 0x4000>;
		interrupts = <0x00 0x63 0x04>;
		clocks = <0x0e 0xb2 0x0e 0xb3 0x0e 0x18c 0x0e 0x18d>;
		clock-names = "biu\0ciu\0ciu-drive\0ciu-sample";
		fifo-depth = <0x100>;
		max-frequency = <0x8f0d180>;
		resets = <0x0e 0xd6>;
		reset-names = "reset";
		status = "okay";
		bus-width = <0x04>;
		cap-sd-highspeed;
		cap-sdio-irq;
		disable-wp;
		keep-power-in-suspend;
		mmc-pwrseq = <0x69>;
		non-removable;
		vmmc-supply = <0x24>;
		vqmmc-supply = <0x46>;
		pinctrl-names = "default";
		pinctrl-0 = <0x6a 0x6b 0x6c 0x6d 0x6e>;
	};

	spi@fe300000 {
		compatible = "rockchip,sfc";
		reg = <0x00 0xfe300000 0x00 0x4000>;
		interrupts = <0x00 0x65 0x04>;
		clocks = <0x0e 0x78 0x0e 0x76>;
		clock-names = "clk_sfc\0hclk_sfc";
		pinctrl-0 = <0x6f>;
		pinctrl-names = "default";
		status = "disabled";
	};

	mmc@fe310000 {
		compatible = "rockchip,rk3568-dwcmshc";
		reg = <0x00 0xfe310000 0x00 0x10000>;
		interrupts = <0x00 0x13 0x04>;
		assigned-clocks = <0x0e 0x7b 0x0e 0x7d>;
		assigned-clock-rates = <0xbebc200 0x16e3600>;
		clocks = <0x0e 0x7c 0x0e 0x7a 0x0e 0x79 0x0e 0x7b 0x0e 0x7d>;
		clock-names = "core\0bus\0axi\0block\0timer";
		status = "okay";
		bus-width = <0x08>;
		mmc-hs200-1_8v;
		non-removable;
		vmmc-supply = <0x1b>;
		vqmmc-supply = <0x19>;
	};

	i2s@fe400000 {
		compatible = "rockchip,rk3568-i2s-tdm";
		reg = <0x00 0xfe400000 0x00 0x1000>;
		interrupts = <0x00 0x34 0x04>;
		assigned-clocks = <0x0e 0x3d 0x0e 0x41>;
		assigned-clock-rates = <0x46cf7100 0x46cf7100>;
		clocks = <0x0e 0x3f 0x0e 0x43 0x0e 0x39>;
		clock-names = "mclk_tx\0mclk_rx\0hclk";
		dmas = <0x70 0x00>;
		dma-names = "tx";
		resets = <0x0e 0x50 0x0e 0x51>;
		reset-names = "tx-m\0rx-m";
		rockchip,grf = <0x1e>;
		#sound-dai-cells = <0x00>;
		status = "okay";
		phandle = <0x08>;
	};

	i2s@fe410000 {
		compatible = "rockchip,rk3568-i2s-tdm";
		reg = <0x00 0xfe410000 0x00 0x1000>;
		interrupts = <0x00 0x35 0x04>;
		assigned-clocks = <0x0e 0x45 0x0e 0x49>;
		assigned-clock-rates = <0x46cf7100 0x46cf7100>;
		clocks = <0x0e 0x47 0x0e 0x4b 0x0e 0x3a>;
		clock-names = "mclk_tx\0mclk_rx\0hclk";
		dmas = <0x70 0x03 0x70 0x02>;
		dma-names = "rx\0tx";
		resets = <0x0e 0x52 0x0e 0x53>;
		reset-names = "tx-m\0rx-m";
		rockchip,grf = <0x1e>;
		pinctrl-names = "default";
		pinctrl-0 = <0x71 0x72 0x73 0x74>;
		#sound-dai-cells = <0x00>;
		status = "okay";
		rockchip,trcm-sync-tx-only;
		phandle = <0xce>;
	};

	i2s@fe420000 {
		compatible = "rockchip,rk3568-i2s-tdm";
		reg = <0x00 0xfe420000 0x00 0x1000>;
		interrupts = <0x00 0x36 0x04>;
		assigned-clocks = <0x0e 0x4d>;
		assigned-clock-rates = <0x46cf7100>;
		clocks = <0x0e 0x4f 0x0e 0x4f 0x0e 0x3b>;
		clock-names = "mclk_tx\0mclk_rx\0hclk";
		dmas = <0x70 0x04 0x70 0x05>;
		dma-names = "tx\0rx";
		resets = <0x0e 0x54>;
		reset-names = "m";
		rockchip,grf = <0x1e>;
		pinctrl-names = "default";
		pinctrl-0 = <0x75 0x76 0x77 0x78>;
		#sound-dai-cells = <0x00>;
		status = "disabled";
	};

	i2s@fe430000 {
		compatible = "rockchip,rk3568-i2s-tdm";
		reg = <0x00 0xfe430000 0x00 0x1000>;
		interrupts = <0x00 0x37 0x04>;
		clocks = <0x0e 0x53 0x0e 0x57 0x0e 0x3c>;
		clock-names = "mclk_tx\0mclk_rx\0hclk";
		dmas = <0x70 0x06 0x70 0x07>;
		dma-names = "tx\0rx";
		resets = <0x0e 0x55 0x0e 0x56>;
		reset-names = "tx-m\0rx-m";
		rockchip,grf = <0x1e>;
		#sound-dai-cells = <0x00>;
		status = "disabled";
	};

	pdm@fe440000 {
		compatible = "rockchip,rk3568-pdm";
		reg = <0x00 0xfe440000 0x00 0x1000>;
		interrupts = <0x00 0x4c 0x04>;
		clocks = <0x0e 0x5a 0x0e 0x59>;
		clock-names = "pdm_clk\0pdm_hclk";
		dmas = <0x70 0x09>;
		dma-names = "rx";
		pinctrl-0 = <0x79 0x7a 0x7b 0x7c 0x7d 0x7e>;
		pinctrl-names = "default";
		resets = <0x0e 0x58>;
		reset-names = "pdm-m";
		#sound-dai-cells = <0x00>;
		status = "disabled";
	};

	spdif@fe460000 {
		compatible = "rockchip,rk3568-spdif";
		reg = <0x00 0xfe460000 0x00 0x1000>;
		interrupts = <0x00 0x66 0x04>;
		clock-names = "mclk\0hclk";
		clocks = <0x0e 0x5f 0x0e 0x5c>;
		dmas = <0x70 0x01>;
		dma-names = "tx";
		pinctrl-names = "default";
		pinctrl-0 = <0x7f>;
		#sound-dai-cells = <0x00>;
		status = "disabled";
	};

	dma-controller@fe530000 {
		compatible = "arm,pl330\0arm,primecell";
		reg = <0x00 0xfe530000 0x00 0x4000>;
		interrupts = <0x00 0x0e 0x04 0x00 0x0d 0x04>;
		arm,pl330-periph-burst;
		clocks = <0x0e 0x10d>;
		clock-names = "apb_pclk";
		#dma-cells = <0x01>;
		phandle = <0x25>;
	};

	dma-controller@fe550000 {
		compatible = "arm,pl330\0arm,primecell";
		reg = <0x00 0xfe550000 0x00 0x4000>;
		interrupts = <0x00 0x10 0x04 0x00 0x0f 0x04>;
		arm,pl330-periph-burst;
		clocks = <0x0e 0x10d>;
		clock-names = "apb_pclk";
		#dma-cells = <0x01>;
		phandle = <0x70>;
	};

	i2c@fe5a0000 {
		compatible = "rockchip,rk3568-i2c\0rockchip,rk3399-i2c";
		reg = <0x00 0xfe5a0000 0x00 0x1000>;
		interrupts = <0x00 0x2f 0x04>;
		clocks = <0x0e 0x148 0x0e 0x147>;
		clock-names = "i2c\0pclk";
		pinctrl-0 = <0x80>;
		pinctrl-names = "default";
		#address-cells = <0x01>;
		#size-cells = <0x00>;
		status = "disabled";
	};

	i2c@fe5b0000 {
		compatible = "rockchip,rk3568-i2c\0rockchip,rk3399-i2c";
		reg = <0x00 0xfe5b0000 0x00 0x1000>;
		interrupts = <0x00 0x30 0x04>;
		clocks = <0x0e 0x14a 0x0e 0x149>;
		clock-names = "i2c\0pclk";
		pinctrl-0 = <0x81>;
		pinctrl-names = "default";
		#address-cells = <0x01>;
		#size-cells = <0x00>;
		status = "okay";

		hym8563@51 {
			compatible = "haoyu,hym8563", "nxp,pcf8563";
			reg = <0x51>;
			#clock-cells = <0x00>;
			wakeup-source;
		};
	};

	i2c@fe5c0000 {
		compatible = "rockchip,rk3568-i2c\0rockchip,rk3399-i2c";
		reg = <0x00 0xfe5c0000 0x00 0x1000>;
		interrupts = <0x00 0x31 0x04>;
		clocks = <0x0e 0x14c 0x0e 0x14b>;
		clock-names = "i2c\0pclk";
		pinctrl-0 = <0x82>;
		pinctrl-names = "default";
		#address-cells = <0x01>;
		#size-cells = <0x00>;
		status = "disabled";
	};

	i2c@fe5d0000 {
		compatible = "rockchip,rk3568-i2c\0rockchip,rk3399-i2c";
		reg = <0x00 0xfe5d0000 0x00 0x1000>;
		interrupts = <0x00 0x32 0x04>;
		clocks = <0x0e 0x14e 0x0e 0x14d>;
		clock-names = "i2c\0pclk";
		pinctrl-0 = <0x83>;
		pinctrl-names = "default";
		#address-cells = <0x01>;
		#size-cells = <0x00>;
		status = "disabled";
	};

	i2c@fe5e0000 {
		compatible = "rockchip,rk3568-i2c\0rockchip,rk3399-i2c";
		reg = <0x00 0xfe5e0000 0x00 0x1000>;
		interrupts = <0x00 0x33 0x04>;
		clocks = <0x0e 0x150 0x0e 0x14f>;
		clock-names = "i2c\0pclk";
		pinctrl-0 = <0x84>;
		pinctrl-names = "default";
		#address-cells = <0x01>;
		#size-cells = <0x00>;
		status = "disabled";
	};

	watchdog@fe600000 {
		compatible = "rockchip,rk3568-wdt\0snps,dw-wdt";
		reg = <0x00 0xfe600000 0x00 0x100>;
		interrupts = <0x00 0x95 0x04>;
		clocks = <0x0e 0x116 0x0e 0x115>;
		clock-names = "tclk\0pclk";
	};

	spi@fe610000 {
		compatible = "rockchip,rk3568-spi\0rockchip,rk3066-spi";
		reg = <0x00 0xfe610000 0x00 0x1000>;
		interrupts = <0x00 0x67 0x04>;
		clocks = <0x0e 0x152 0x0e 0x151>;
		clock-names = "spiclk\0apb_pclk";
		dmas = <0x25 0x14 0x25 0x15>;
		dma-names = "tx\0rx";
		pinctrl-names = "default";
		pinctrl-0 = <0x85 0x86 0x87>;
		#address-cells = <0x01>;
		#size-cells = <0x00>;
		status = "disabled";
	};

	spi@fe620000 {
		compatible = "rockchip,rk3568-spi\0rockchip,rk3066-spi";
		reg = <0x00 0xfe620000 0x00 0x1000>;
		interrupts = <0x00 0x68 0x04>;
		clocks = <0x0e 0x154 0x0e 0x153>;
		clock-names = "spiclk\0apb_pclk";
		dmas = <0x25 0x16 0x25 0x17>;
		dma-names = "tx\0rx";
		pinctrl-names = "default";
		pinctrl-0 = <0x88 0x89 0x8a>;
		#address-cells = <0x01>;
		#size-cells = <0x00>;
		status = "disabled";
	};

	spi@fe630000 {
		compatible = "rockchip,rk3568-spi\0rockchip,rk3066-spi";
		reg = <0x00 0xfe630000 0x00 0x1000>;
		interrupts = <0x00 0x69 0x04>;
		clocks = <0x0e 0x156 0x0e 0x155>;
		clock-names = "spiclk\0apb_pclk";
		dmas = <0x25 0x18 0x25 0x19>;
		dma-names = "tx\0rx";
		pinctrl-names = "default";
		pinctrl-0 = <0x8b 0x8c 0x8d>;
		#address-cells = <0x01>;
		#size-cells = <0x00>;
		status = "disabled";
	};

	spi@fe640000 {
		compatible = "rockchip,rk3568-spi\0rockchip,rk3066-spi";
		reg = <0x00 0xfe640000 0x00 0x1000>;
		interrupts = <0x00 0x6a 0x04>;
		clocks = <0x0e 0x158 0x0e 0x157>;
		clock-names = "spiclk\0apb_pclk";
		dmas = <0x25 0x1a 0x25 0x1b>;
		dma-names = "tx\0rx";
		pinctrl-names = "default";
		pinctrl-0 = <0x8e 0x8f 0x90>;
		#address-cells = <0x01>;
		#size-cells = <0x00>;
		status = "disabled";
	};

	serial@fe650000 {
		compatible = "rockchip,rk3568-uart\0snps,dw-apb-uart";
		reg = <0x00 0xfe650000 0x00 0x100>;
		interrupts = <0x00 0x75 0x04>;
		clocks = <0x0e 0x11f 0x0e 0x11c>;
		clock-names = "baudclk\0apb_pclk";
		dmas = <0x25 0x02 0x25 0x03>;
		pinctrl-0 = <0x91 0x92 0x93>;
		pinctrl-names = "default";
		reg-io-width = <0x04>;
		reg-shift = <0x02>;
		status = "okay";
		uart-has-rtscts;

		bluetooth {
			compatible = "brcm,bcm43438-bt";
			clocks = <0x94 0x01>;
			clock-names = "lpo";
			device-wake-gpios = <0x95 0x11 0x00>;
			host-wake-gpios = <0x95 0x10 0x00>;
			shutdown-gpios = <0x95 0x0f 0x00>;
			pinctrl-names = "default";
			pinctrl-0 = <0x96 0x97 0x98>;
			vbat-supply = <0x24>;
			vddio-supply = <0x46>;
		};
	};

	serial@fe660000 {
		compatible = "rockchip,rk3568-uart\0snps,dw-apb-uart";
		reg = <0x00 0xfe660000 0x00 0x100>;
		interrupts = <0x00 0x76 0x04>;
		clocks = <0x0e 0x123 0x0e 0x120>;
		clock-names = "baudclk\0apb_pclk";
		dmas = <0x25 0x04 0x25 0x05>;
		pinctrl-0 = <0x99>;
		pinctrl-names = "default";
		reg-io-width = <0x04>;
		reg-shift = <0x02>;
		status = "okay";
	};

	serial@fe670000 {
		compatible = "rockchip,rk3568-uart\0snps,dw-apb-uart";
		reg = <0x00 0xfe670000 0x00 0x100>;
		interrupts = <0x00 0x77 0x04>;
		clocks = <0x0e 0x127 0x0e 0x124>;
		clock-names = "baudclk\0apb_pclk";
		dmas = <0x25 0x06 0x25 0x07>;
		pinctrl-0 = <0x9a>;
		pinctrl-names = "default";
		reg-io-width = <0x04>;
		reg-shift = <0x02>;
		status = "okay";
	};

	serial@fe680000 {
		compatible = "rockchip,rk3568-uart\0snps,dw-apb-uart";
		reg = <0x00 0xfe680000 0x00 0x100>;
		interrupts = <0x00 0x78 0x04>;
		clocks = <0x0e 0x12b 0x0e 0x128>;
		clock-names = "baudclk\0apb_pclk";
		dmas = <0x25 0x08 0x25 0x09>;
		pinctrl-0 = <0x9b>;
		pinctrl-names = "default";
		reg-io-width = <0x04>;
		reg-shift = <0x02>;
		status = "disabled";
	};

	serial@fe690000 {
		compatible = "rockchip,rk3568-uart\0snps,dw-apb-uart";
		reg = <0x00 0xfe690000 0x00 0x100>;
		interrupts = <0x00 0x79 0x04>;
		clocks = <0x0e 0x12f 0x0e 0x12c>;
		clock-names = "baudclk\0apb_pclk";
		dmas = <0x25 0x0a 0x25 0x0b>;
		pinctrl-0 = <0x9c>;
		pinctrl-names = "default";
		reg-io-width = <0x04>;
		reg-shift = <0x02>;
		status = "disabled";
	};

	serial@fe6a0000 {
		compatible = "rockchip,rk3568-uart\0snps,dw-apb-uart";
		reg = <0x00 0xfe6a0000 0x00 0x100>;
		interrupts = <0x00 0x7a 0x04>;
		clocks = <0x0e 0x133 0x0e 0x130>;
		clock-names = "baudclk\0apb_pclk";
		dmas = <0x25 0x0c 0x25 0x0d>;
		pinctrl-0 = <0x9d>;
		pinctrl-names = "default";
		reg-io-width = <0x04>;
		reg-shift = <0x02>;
		status = "disabled";
	};

	serial@fe6b0000 {
		compatible = "rockchip,rk3568-uart\0snps,dw-apb-uart";
		reg = <0x00 0xfe6b0000 0x00 0x100>;
		interrupts = <0x00 0x7b 0x04>;
		clocks = <0x0e 0x137 0x0e 0x134>;
		clock-names = "baudclk\0apb_pclk";
		dmas = <0x25 0x0e 0x25 0x0f>;
		pinctrl-0 = <0x9e>;
		pinctrl-names = "default";
		reg-io-width = <0x04>;
		reg-shift = <0x02>;
		status = "disabled";
	};

	serial@fe6c0000 {
		compatible = "rockchip,rk3568-uart\0snps,dw-apb-uart";
		reg = <0x00 0xfe6c0000 0x00 0x100>;
		interrupts = <0x00 0x7c 0x04>;
		clocks = <0x0e 0x13b 0x0e 0x138>;
		clock-names = "baudclk\0apb_pclk";
		dmas = <0x25 0x10 0x25 0x11>;
		pinctrl-0 = <0x9f>;
		pinctrl-names = "default";
		reg-io-width = <0x04>;
		reg-shift = <0x02>;
		status = "disabled";
	};

	serial@fe6d0000 {
		compatible = "rockchip,rk3568-uart\0snps,dw-apb-uart";
		reg = <0x00 0xfe6d0000 0x00 0x100>;
		interrupts = <0x00 0x7d 0x04>;
		clocks = <0x0e 0x13f 0x0e 0x13c>;
		clock-names = "baudclk\0apb_pclk";
		dmas = <0x25 0x12 0x25 0x13>;
		pinctrl-0 = <0xa0>;
		pinctrl-names = "default";
		reg-io-width = <0x04>;
		reg-shift = <0x02>;
		status = "disabled";
	};

	thermal-zones {

		cpu-thermal {
			polling-delay-passive = <0x64>;
			polling-delay = <0x3e8>;
			thermal-sensors = <0xa1 0x00>;

			trips {

				cpu_alert0 {
					temperature = <0x11170>;
					hysteresis = <0x7d0>;
					type = "passive";
					phandle = <0xa2>;
				};

				cpu_alert1 {
					temperature = <0x124f8>;
					hysteresis = <0x7d0>;
					type = "passive";
				};

				cpu_crit {
					temperature = <0x17318>;
					hysteresis = <0x7d0>;
					type = "critical";
				};

				cpu_hot {
					temperature = <0xd6d8>;
					hysteresis = <0x7d0>;
					type = "active";
				};
			};

			cooling-maps {

				map0 {
					trip = <0xa2>;
					cooling-device = <0x09 0xffffffff 0xffffffff 0x0a 0xffffffff 0xffffffff 0x0b 0xffffffff 0xffffffff 0x0c 0xffffffff 0xffffffff>;
				};
			};
		};

		gpu-thermal {
			polling-delay-passive = <0x14>;
			polling-delay = <0x3e8>;
			thermal-sensors = <0xa1 0x01>;

			trips {

				gpu-threshold {
					temperature = <0x11170>;
					hysteresis = <0x7d0>;
					type = "passive";
				};

				gpu-target {
					temperature = <0x124f8>;
					hysteresis = <0x7d0>;
					type = "passive";
					phandle = <0xa3>;
				};

				gpu-crit {
					temperature = <0x17318>;
					hysteresis = <0x7d0>;
					type = "critical";
				};
			};

			cooling-maps {

				map0 {
					trip = <0xa3>;
					cooling-device = <0xa4 0xffffffff 0xffffffff>;
				};
			};
		};
	};

	tsadc@fe710000 {
		compatible = "rockchip,rk3568-tsadc";
		reg = <0x00 0xfe710000 0x00 0x100>;
		interrupts = <0x00 0x73 0x04>;
		assigned-clocks = <0x0e 0x110 0x0e 0x111>;
		assigned-clock-rates = <0x1036640 0xaae60>;
		clocks = <0x0e 0x111 0x0e 0x10f>;
		clock-names = "tsadc\0apb_pclk";
		resets = <0x0e 0x181 0x0e 0x182 0x0e 0x1d7>;
		rockchip,grf = <0x1e>;
		rockchip,hw-tshut-temp = <0x17318>;
		pinctrl-names = "init\0default\0sleep";
		pinctrl-0 = <0xa5>;
		pinctrl-1 = <0xa6>;
		pinctrl-2 = <0xa5>;
		#thermal-sensor-cells = <0x01>;
		status = "okay";
		phandle = <0xa1>;
	};

	saradc@fe720000 {
		compatible = "rockchip,rk3568-saradc\0rockchip,rk3399-saradc";
		reg = <0x00 0xfe720000 0x00 0x100>;
		interrupts = <0x00 0x5d 0x04>;
		clocks = <0x0e 0x113 0x0e 0x112>;
		clock-names = "saradc\0apb_pclk";
		resets = <0x0e 0x180>;
		reset-names = "saradc-apb";
		#io-channel-cells = <0x01>;
		status = "okay";
		vref-supply = <0xa7>;
		phandle = <0xd0>;
	};

	pwm@fe6e0000 {
		compatible = "rockchip,rk3568-pwm\0rockchip,rk3328-pwm";
		reg = <0x00 0xfe6e0000 0x00 0x10>;
		clocks = <0x0e 0x15a 0x0e 0x159>;
		clock-names = "pwm\0pclk";
		pinctrl-0 = <0xa8>;
		pinctrl-names = "default";
		#pwm-cells = <0x03>;
		status = "disabled";
	};

	pwm@fe6e0010 {
		compatible = "rockchip,rk3568-pwm\0rockchip,rk3328-pwm";
		reg = <0x00 0xfe6e0010 0x00 0x10>;
		clocks = <0x0e 0x15a 0x0e 0x159>;
		clock-names = "pwm\0pclk";
		pinctrl-0 = <0xa9>;
		pinctrl-names = "default";
		#pwm-cells = <0x03>;
		status = "disabled";
	};

	pwm@fe6e0020 {
		compatible = "rockchip,rk3568-pwm\0rockchip,rk3328-pwm";
		reg = <0x00 0xfe6e0020 0x00 0x10>;
		clocks = <0x0e 0x15a 0x0e 0x159>;
		clock-names = "pwm\0pclk";
		pinctrl-0 = <0xaa>;
		pinctrl-names = "default";
		#pwm-cells = <0x03>;
		status = "disabled";
	};

	pwm@fe6e0030 {
		compatible = "rockchip,rk3568-pwm\0rockchip,rk3328-pwm";
		reg = <0x00 0xfe6e0030 0x00 0x10>;
		clocks = <0x0e 0x15a 0x0e 0x159>;
		clock-names = "pwm\0pclk";
		pinctrl-0 = <0xab>;
		pinctrl-names = "default";
		#pwm-cells = <0x03>;
		status = "disabled";
	};

	pwm@fe6f0000 {
		compatible = "rockchip,rk3568-pwm\0rockchip,rk3328-pwm";
		reg = <0x00 0xfe6f0000 0x00 0x10>;
		clocks = <0x0e 0x15d 0x0e 0x15c>;
		clock-names = "pwm\0pclk";
		pinctrl-0 = <0xac>;
		pinctrl-names = "default";
		#pwm-cells = <0x03>;
		status = "disabled";
	};

	pwm@fe6f0010 {
		compatible = "rockchip,rk3568-pwm\0rockchip,rk3328-pwm";
		reg = <0x00 0xfe6f0010 0x00 0x10>;
		clocks = <0x0e 0x15d 0x0e 0x15c>;
		clock-names = "pwm\0pclk";
		pinctrl-0 = <0xad>;
		pinctrl-names = "default";
		#pwm-cells = <0x03>;
		status = "disabled";
	};

	pwm@fe6f0020 {
		compatible = "rockchip,rk3568-pwm\0rockchip,rk3328-pwm";
		reg = <0x00 0xfe6f0020 0x00 0x10>;
		clocks = <0x0e 0x15d 0x0e 0x15c>;
		clock-names = "pwm\0pclk";
		pinctrl-0 = <0xae>;
		pinctrl-names = "default";
		#pwm-cells = <0x03>;
		status = "disabled";
	};

	pwm@fe6f0030 {
		compatible = "rockchip,rk3568-pwm\0rockchip,rk3328-pwm";
		reg = <0x00 0xfe6f0030 0x00 0x10>;
		clocks = <0x0e 0x15d 0x0e 0x15c>;
		clock-names = "pwm\0pclk";
		pinctrl-0 = <0xaf>;
		pinctrl-names = "default";
		#pwm-cells = <0x03>;
		status = "disabled";
	};

	pwm@fe700000 {
		compatible = "rockchip,rk3568-pwm\0rockchip,rk3328-pwm";
		reg = <0x00 0xfe700000 0x00 0x10>;
		clocks = <0x0e 0x160 0x0e 0x15f>;
		clock-names = "pwm\0pclk";
		pinctrl-0 = <0xb0>;
		pinctrl-names = "default";
		#pwm-cells = <0x03>;
		status = "disabled";
	};

	pwm@fe700010 {
		compatible = "rockchip,rk3568-pwm\0rockchip,rk3328-pwm";
		reg = <0x00 0xfe700010 0x00 0x10>;
		clocks = <0x0e 0x160 0x0e 0x15f>;
		clock-names = "pwm\0pclk";
		pinctrl-0 = <0xb1>;
		pinctrl-names = "default";
		#pwm-cells = <0x03>;
		status = "disabled";
	};

	pwm@fe700020 {
		compatible = "rockchip,rk3568-pwm\0rockchip,rk3328-pwm";
		reg = <0x00 0xfe700020 0x00 0x10>;
		clocks = <0x0e 0x160 0x0e 0x15f>;
		clock-names = "pwm\0pclk";
		pinctrl-0 = <0xb2>;
		pinctrl-names = "default";
		#pwm-cells = <0x03>;
		status = "disabled";
	};

	pwm@fe700030 {
		compatible = "rockchip,rk3568-pwm\0rockchip,rk3328-pwm";
		reg = <0x00 0xfe700030 0x00 0x10>;
		clocks = <0x0e 0x160 0x0e 0x15f>;
		clock-names = "pwm\0pclk";
		pinctrl-0 = <0xb3>;
		pinctrl-names = "default";
		#pwm-cells = <0x03>;
		status = "disabled";
	};

	phy@fe830000 {
		compatible = "rockchip,rk3568-naneng-combphy";
		reg = <0x00 0xfe830000 0x00 0x100>;
		clocks = <0x1d 0x22 0x0e 0x17d 0x0e 0x7f>;
		clock-names = "ref\0apb\0pipe";
		assigned-clocks = <0x1d 0x22>;
		assigned-clock-rates = <0x5f5e100>;
		resets = <0x0e 0x1c7>;
		rockchip,pipe-grf = <0xb4>;
		rockchip,pipe-phy-grf = <0xb5>;
		#phy-cells = <0x01>;
		status = "okay";
		phandle = <0x0f>;
	};

	phy@fe840000 {
		compatible = "rockchip,rk3568-naneng-combphy";
		reg = <0x00 0xfe840000 0x00 0x100>;
		clocks = <0x1d 0x25 0x0e 0x17e 0x0e 0x7f>;
		clock-names = "ref\0apb\0pipe";
		assigned-clocks = <0x1d 0x25>;
		assigned-clock-rates = <0x5f5e100>;
		resets = <0x0e 0x1c9>;
		rockchip,pipe-grf = <0xb4>;
		rockchip,pipe-phy-grf = <0xb6>;
		#phy-cells = <0x01>;
		status = "okay";
		phandle = <0x11>;
	};

	phy@fe870000 {
		compatible = "rockchip,rk3568-csi-dphy";
		reg = <0x00 0xfe870000 0x00 0x10000>;
		clocks = <0x0e 0x179>;
		clock-names = "pclk";
		#phy-cells = <0x00>;
		resets = <0x0e 0x1ba>;
		reset-names = "apb";
		rockchip,grf = <0x1e>;
		status = "disabled";
	};

	mipi-dphy@fe850000 {
		compatible = "rockchip,rk3568-dsi-dphy";
		reg = <0x00 0xfe850000 0x00 0x10000>;
		clock-names = "ref\0pclk";
		clocks = <0x1d 0x17 0x0e 0x17a>;
		#phy-cells = <0x00>;
		power-domains = <0x10 0x09>;
		reset-names = "apb";
		resets = <0x0e 0x1bb>;
		status = "disabled";
		phandle = <0x57>;
	};

	mipi-dphy@fe860000 {
		compatible = "rockchip,rk3568-dsi-dphy";
		reg = <0x00 0xfe860000 0x00 0x10000>;
		clock-names = "ref\0pclk";
		clocks = <0x1d 0x19 0x0e 0x17b>;
		#phy-cells = <0x00>;
		power-domains = <0x10 0x09>;
		reset-names = "apb";
		resets = <0x0e 0x1bc>;
		status = "disabled";
		phandle = <0x58>;
	};

	usb2phy@fe8a0000 {
		compatible = "rockchip,rk3568-usb2phy";
		reg = <0x00 0xfe8a0000 0x00 0x10000>;
		clocks = <0x1d 0x13>;
		clock-names = "phyclk";
		clock-output-names = "clk_usbphy0_480m";
		interrupts = <0x00 0x87 0x04>;
		rockchip,usbgrf = <0xb7>;
		#clock-cells = <0x00>;
		status = "okay";
		phandle = <0x13>;

		host-port {
			#phy-cells = <0x00>;
			status = "okay";
			phy-supply = <0xb8>;
			phandle = <0x14>;
		};

		otg-port {
			#phy-cells = <0x00>;
			status = "okay";
			vbus-supply = <0xb9>;
			phandle = <0x12>;
		};
	};

	usb2phy@fe8b0000 {
		compatible = "rockchip,rk3568-usb2phy";
		reg = <0x00 0xfe8b0000 0x00 0x10000>;
		clocks = <0x1d 0x15>;
		clock-names = "phyclk";
		clock-output-names = "clk_usbphy1_480m";
		interrupts = <0x00 0x88 0x04>;
		rockchip,usbgrf = <0xba>;
		#clock-cells = <0x00>;
		status = "okay";

		host-port {
			#phy-cells = <0x00>;
			status = "okay";
			phy-supply = <0xb8>;
			phandle = <0x16>;
		};

		otg-port {
			#phy-cells = <0x00>;
			status = "okay";
			phy-supply = <0xb8>;
			phandle = <0x15>;
		};
	};

	pinctrl {
		compatible = "rockchip,rk3568-pinctrl";
		rockchip,grf = <0x1e>;
		rockchip,pmu = <0xbb>;
		#address-cells = <0x02>;
		#size-cells = <0x02>;
		ranges;
		phandle = <0xbc>;

		gpio@fdd60000 {
			compatible = "rockchip,gpio-bank";
			reg = <0x00 0xfdd60000 0x00 0x100>;
			interrupts = <0x00 0x21 0x04>;
			clocks = <0x1d 0x2e 0x1d 0x0c>;
			gpio-controller;
			gpio-ranges = <0xbc 0x00 0x00 0x20>;
			#gpio-cells = <0x02>;
			interrupt-controller;
			#interrupt-cells = <0x02>;
			phandle = <0x21>;
		};

		gpio@fe740000 {
			compatible = "rockchip,gpio-bank";
			reg = <0x00 0xfe740000 0x00 0x100>;
			interrupts = <0x00 0x22 0x04>;
			clocks = <0x0e 0x163 0x0e 0x164>;
			gpio-controller;
			gpio-ranges = <0xbc 0x00 0x20 0x20>;
			#gpio-cells = <0x02>;
			interrupt-controller;
			#interrupt-cells = <0x02>;
			phandle = <0x62>;
		};

		gpio@fe750000 {
			compatible = "rockchip,gpio-bank";
			reg = <0x00 0xfe750000 0x00 0x100>;
			interrupts = <0x00 0x23 0x04>;
			clocks = <0x0e 0x165 0x0e 0x166>;
			gpio-controller;
			gpio-ranges = <0xbc 0x00 0x40 0x20>;
			#gpio-cells = <0x02>;
			interrupt-controller;
			#interrupt-cells = <0x02>;
			phandle = <0x95>;
		};

		gpio@fe760000 {
			compatible = "rockchip,gpio-bank";
			reg = <0x00 0xfe760000 0x00 0x100>;
			interrupts = <0x00 0x24 0x04>;
			clocks = <0x0e 0x167 0x0e 0x168>;
			gpio-controller;
			gpio-ranges = <0xbc 0x00 0x60 0x20>;
			#gpio-cells = <0x02>;
			interrupt-controller;
			#interrupt-cells = <0x02>;
		};

		gpio@fe770000 {
			compatible = "rockchip,gpio-bank";
			reg = <0x00 0xfe770000 0x00 0x100>;
			interrupts = <0x00 0x25 0x04>;
			clocks = <0x0e 0x169 0x0e 0x16a>;
			gpio-controller;
			gpio-ranges = <0xbc 0x00 0x80 0x20>;
			#gpio-cells = <0x02>;
			interrupt-controller;
			#interrupt-cells = <0x02>;
		};

		pcfg-pull-up {
			bias-pull-up;
			phandle = <0xbf>;
		};

		pcfg-pull-down {
			bias-pull-down;
			phandle = <0xc5>;
		};

		pcfg-pull-none {
			bias-disable;
			phandle = <0xbd>;
		};

		pcfg-pull-none-drv-level-1 {
			bias-disable;
			drive-strength = <0x01>;
			phandle = <0xc1>;
		};

		pcfg-pull-none-drv-level-2 {
			bias-disable;
			drive-strength = <0x02>;
			phandle = <0xc0>;
		};

		pcfg-pull-none-drv-level-3 {
			bias-disable;
			drive-strength = <0x03>;
			phandle = <0xc4>;
		};

		pcfg-pull-up-drv-level-1 {
			bias-pull-up;
			drive-strength = <0x01>;
			phandle = <0xc3>;
		};

		pcfg-pull-up-drv-level-2 {
			bias-pull-up;
			drive-strength = <0x02>;
			phandle = <0xbe>;
		};

		pcfg-pull-none-smt {
			bias-disable;
			input-schmitt-enable;
			phandle = <0xc2>;
		};

		acodec {
		};

		audiopwm {
		};

		bt656 {
		};

		bt1120 {
		};

		cam {
		};

		can0 {
		};

		can1 {
		};

		can2 {
		};

		cif {
		};

		clk32k {

			clk32k-out0 {
				rockchip,pins = <0x00 0x08 0x02 0xbd>;
				phandle = <0x0d>;
			};
		};

		cpu {
		};

		ebc {
		};

		edpdp {
		};

		emmc {
		};

		eth0 {
		};

		eth1 {
		};

		flash {
		};

		fspi {

			fspi-pins {
				rockchip,pins = <0x01 0x18 0x01 0xbd 0x01 0x1b 0x01 0xbd 0x01 0x19 0x01 0xbd 0x01 0x1a 0x01 0xbd 0x01 0x17 0x02 0xbd 0x01 0x1c 0x01 0xbd>;
				phandle = <0x6f>;
			};
		};

		gmac0 {
		};

		gmac1 {

			gmac1m0-miim {
				rockchip,pins = <0x03 0x14 0x03 0xbd 0x03 0x15 0x03 0xbd>;
				phandle = <0x4e>;
			};

			gmac1m0-clkinout {
				rockchip,pins = <0x03 0x10 0x03 0xbd>;
				phandle = <0x52>;
			};

			gmac1m0-rx-bus2 {
				rockchip,pins = <0x03 0x09 0x03 0xbd 0x03 0x0a 0x03 0xbd 0x03 0x0b 0x03 0xbd>;
				phandle = <0x50>;
			};

			gmac1m0-tx-bus2 {
				rockchip,pins = <0x03 0x0d 0x03 0xc0 0x03 0x0e 0x03 0xc0 0x03 0x0f 0x03 0xbd>;
				phandle = <0x4f>;
			};

			gmac1m0-rgmii-clk {
				rockchip,pins = <0x03 0x07 0x03 0xbd 0x03 0x06 0x03 0xc1>;
				phandle = <0x51>;
			};

			gmac1m0-rgmii-bus {
				rockchip,pins = <0x03 0x04 0x03 0xbd 0x03 0x05 0x03 0xbd 0x03 0x02 0x03 0xc0 0x03 0x03 0x03 0xc0>;
				phandle = <0x53>;
			};
		};

		gpu {
		};

		hdmitx {

			hdmitxm0-cec {
				rockchip,pins = <0x04 0x19 0x01 0xbd>;
				phandle = <0x5b>;
			};

			hdmitx-scl {
				rockchip,pins = <0x04 0x17 0x01 0xbd>;
				phandle = <0x59>;
			};

			hdmitx-sda {
				rockchip,pins = <0x04 0x18 0x01 0xbd>;
				phandle = <0x5a>;
			};
		};

		i2c0 {

			i2c0-xfer {
				rockchip,pins = <0x00 0x09 0x01 0xc2 0x00 0x0a 0x01 0xc2>;
				phandle = <0x1f>;
			};
		};

		i2c1 {

			i2c1-xfer {
				rockchip,pins = <0x00 0x0b 0x01 0xc2 0x00 0x0c 0x01 0xc2>;
				phandle = <0x80>;
			};
		};

		i2c2 {

			i2c2m0-xfer {
				rockchip,pins = <0x00 0x0d 0x01 0xc2 0x00 0x0e 0x01 0xc2>;
				phandle = <0x81>;
			};
		};

		i2c3 {

			i2c3m0-xfer {
				rockchip,pins = <0x01 0x01 0x01 0xc2 0x01 0x00 0x01 0xc2>;
				phandle = <0x82>;
			};
		};

		i2c4 {

			i2c4m0-xfer {
				rockchip,pins = <0x04 0x0b 0x01 0xc2 0x04 0x0a 0x01 0xc2>;
				phandle = <0x83>;
			};
		};

		i2c5 {

			i2c5m0-xfer {
				rockchip,pins = <0x03 0x0b 0x04 0xc2 0x03 0x0c 0x04 0xc2>;
				phandle = <0x84>;
			};
		};

		i2s1 {

			i2s1m0-lrcktx {
				rockchip,pins = <0x01 0x05 0x01 0xbd>;
				phandle = <0x72>;
			};

			i2s1m0-mclk {
				rockchip,pins = <0x01 0x02 0x01 0xbd>;
				phandle = <0x23>;
			};

			i2s1m0-sclktx {
				rockchip,pins = <0x01 0x03 0x01 0xbd>;
				phandle = <0x71>;
			};

			i2s1m0-sdi0 {
				rockchip,pins = <0x01 0x0b 0x01 0xbd>;
				phandle = <0x73>;
			};

			i2s1m0-sdo0 {
				rockchip,pins = <0x01 0x07 0x01 0xbd>;
				phandle = <0x74>;
			};
		};

		i2s2 {

			i2s2m0-lrcktx {
				rockchip,pins = <0x02 0x13 0x01 0xbd>;
				phandle = <0x76>;
			};

			i2s2m0-sclktx {
				rockchip,pins = <0x02 0x12 0x01 0xbd>;
				phandle = <0x75>;
			};

			i2s2m0-sdi {
				rockchip,pins = <0x02 0x15 0x01 0xbd>;
				phandle = <0x77>;
			};

			i2s2m0-sdo {
				rockchip,pins = <0x02 0x14 0x01 0xbd>;
				phandle = <0x78>;
			};
		};

		i2s3 {
		};

		isp {
		};

		jtag {
		};

		lcdc {
		};

		mcu {
		};

		npu {
		};

		pcie20 {
		};

		pcie30x1 {
		};

		pcie30x2 {
		};

		pdm {

			pdmm0-clk {
				rockchip,pins = <0x01 0x06 0x03 0xbd>;
				phandle = <0x79>;
			};

			pdmm0-clk1 {
				rockchip,pins = <0x01 0x04 0x03 0xbd>;
				phandle = <0x7a>;
			};

			pdmm0-sdi0 {
				rockchip,pins = <0x01 0x0b 0x02 0xbd>;
				phandle = <0x7b>;
			};

			pdmm0-sdi1 {
				rockchip,pins = <0x01 0x0a 0x03 0xbd>;
				phandle = <0x7c>;
			};

			pdmm0-sdi2 {
				rockchip,pins = <0x01 0x09 0x03 0xbd>;
				phandle = <0x7d>;
			};

			pdmm0-sdi3 {
				rockchip,pins = <0x01 0x08 0x03 0xbd>;
				phandle = <0x7e>;
			};
		};

		pmic {

			pmic_int {
				rockchip,pins = <0x00 0x03 0x00 0xbf>;
				phandle = <0x22>;
			};
		};

		pmu {
		};

		pwm0 {

			pwm0m0-pins {
				rockchip,pins = <0x00 0x0f 0x01 0xbd>;
				phandle = <0x27>;
			};
		};

		pwm1 {

			pwm1m0-pins {
				rockchip,pins = <0x00 0x10 0x01 0xbd>;
				phandle = <0x28>;
			};
		};

		pwm2 {

			pwm2m0-pins {
				rockchip,pins = <0x00 0x11 0x01 0xbd>;
				phandle = <0x29>;
			};
		};

		pwm3 {

			pwm3-pins {
				rockchip,pins = <0x00 0x12 0x01 0xbd>;
				phandle = <0x2a>;
			};
		};

		pwm4 {

			pwm4-pins {
				rockchip,pins = <0x00 0x13 0x01 0xbd>;
				phandle = <0xa8>;
			};
		};

		pwm5 {

			pwm5-pins {
				rockchip,pins = <0x00 0x14 0x01 0xbd>;
				phandle = <0xa9>;
			};
		};

		pwm6 {

			pwm6-pins {
				rockchip,pins = <0x00 0x15 0x01 0xbd>;
				phandle = <0xaa>;
			};
		};

		pwm7 {

			pwm7-pins {
				rockchip,pins = <0x00 0x16 0x01 0xbd>;
				phandle = <0xab>;
			};
		};

		pwm8 {

			pwm8m0-pins {
				rockchip,pins = <0x03 0x09 0x05 0xbd>;
				phandle = <0xac>;
			};
		};

		pwm9 {

			pwm9m0-pins {
				rockchip,pins = <0x03 0x0a 0x05 0xbd>;
				phandle = <0xad>;
			};
		};

		pwm10 {

			pwm10m0-pins {
				rockchip,pins = <0x03 0x0d 0x05 0xbd>;
				phandle = <0xae>;
			};
		};

		pwm11 {

			pwm11m0-pins {
				rockchip,pins = <0x03 0x0e 0x05 0xbd>;
				phandle = <0xaf>;
			};
		};

		pwm12 {

			pwm12m0-pins {
				rockchip,pins = <0x03 0x0f 0x02 0xbd>;
				phandle = <0xb0>;
			};
		};

		pwm13 {

			pwm13m0-pins {
				rockchip,pins = <0x03 0x10 0x02 0xbd>;
				phandle = <0xb1>;
			};
		};

		pwm14 {

			pwm14m0-pins {
				rockchip,pins = <0x03 0x14 0x01 0xbd>;
				phandle = <0xb2>;
			};
		};

		pwm15 {

			pwm15m0-pins {
				rockchip,pins = <0x03 0x15 0x01 0xbd>;
				phandle = <0xb3>;
			};
		};

		refclk {
		};

		sata {
		};

		sata0 {
		};

		sata1 {
		};

		sata2 {
		};

		scr {
		};

		sdmmc0 {

			sdmmc0-bus4 {
				rockchip,pins = <0x01 0x1d 0x01 0xbe 0x01 0x1e 0x01 0xbe 0x01 0x1f 0x01 0xbe 0x02 0x00 0x01 0xbe>;
				phandle = <0x64>;
			};

			sdmmc0-clk {
				rockchip,pins = <0x02 0x02 0x01 0xbe>;
				phandle = <0x65>;
			};

			sdmmc0-cmd {
				rockchip,pins = <0x02 0x01 0x01 0xbe>;
				phandle = <0x66>;
			};

			sdmmc0-det {
				rockchip,pins = <0x00 0x04 0x01 0xbf>;
				phandle = <0x67>;
			};
		};

		sdmmc1 {

			sdmmc1-bus4 {
				rockchip,pins = <0x02 0x03 0x01 0xbe 0x02 0x04 0x01 0xbe 0x02 0x05 0x01 0xbe 0x02 0x06 0x01 0xbe>;
				phandle = <0x6a>;
			};

			sdmmc1-clk {
				rockchip,pins = <0x02 0x08 0x01 0xbe>;
				phandle = <0x6c>;
			};

			sdmmc1-cmd {
				rockchip,pins = <0x02 0x07 0x01 0xbe>;
				phandle = <0x6b>;
			};
		};

		sdmmc2 {

			sdmmc2m0-bus4 {
				rockchip,pins = <0x03 0x16 0x03 0xbe 0x03 0x17 0x03 0xbe 0x03 0x18 0x03 0xbe 0x03 0x19 0x03 0xbe>;
				phandle = <0x47>;
			};

			sdmmc2m0-clk {
				rockchip,pins = <0x03 0x1b 0x03 0xbe>;
				phandle = <0x49>;
			};

			sdmmc2m0-cmd {
				rockchip,pins = <0x03 0x1a 0x03 0xbe>;
				phandle = <0x48>;
			};
		};

		spdif {

			spdifm0-tx {
				rockchip,pins = <0x01 0x04 0x04 0xbd>;
				phandle = <0x7f>;
			};
		};

		spi0 {

			spi0m0-pins {
				rockchip,pins = <0x00 0x0d 0x02 0xbd 0x00 0x15 0x02 0xbd 0x00 0x0e 0x02 0xbd>;
				phandle = <0x87>;
			};

			spi0m0-cs0 {
				rockchip,pins = <0x00 0x16 0x02 0xbd>;
				phandle = <0x85>;
			};

			spi0m0-cs1 {
				rockchip,pins = <0x00 0x14 0x02 0xbd>;
				phandle = <0x86>;
			};
		};

		spi1 {

			spi1m0-pins {
				rockchip,pins = <0x02 0x0d 0x03 0xbd 0x02 0x0e 0x03 0xbd 0x02 0x0f 0x04 0xbd>;
				phandle = <0x8a>;
			};

			spi1m0-cs0 {
				rockchip,pins = <0x02 0x10 0x04 0xbd>;
				phandle = <0x88>;
			};

			spi1m0-cs1 {
				rockchip,pins = <0x02 0x16 0x03 0xbd>;
				phandle = <0x89>;
			};
		};

		spi2 {

			spi2m0-pins {
				rockchip,pins = <0x02 0x11 0x04 0xbd 0x02 0x12 0x04 0xbd 0x02 0x13 0x04 0xbd>;
				phandle = <0x8d>;
			};

			spi2m0-cs0 {
				rockchip,pins = <0x02 0x14 0x04 0xbd>;
				phandle = <0x8b>;
			};

			spi2m0-cs1 {
				rockchip,pins = <0x02 0x15 0x04 0xbd>;
				phandle = <0x8c>;
			};
		};

		spi3 {

			spi3m0-pins {
				rockchip,pins = <0x04 0x0b 0x04 0xbd 0x04 0x08 0x04 0xbd 0x04 0x0a 0x04 0xbd>;
				phandle = <0x90>;
			};

			spi3m0-cs0 {
				rockchip,pins = <0x04 0x06 0x04 0xbd>;
				phandle = <0x8e>;
			};

			spi3m0-cs1 {
				rockchip,pins = <0x04 0x07 0x04 0xbd>;
				phandle = <0x8f>;
			};
		};

		tsadc {

			tsadc-shutorg {
				rockchip,pins = <0x00 0x01 0x02 0xbd>;
				phandle = <0xa6>;
			};

			tsadc-pin {
				rockchip,pins = <0x00 0x01 0x00 0xbd>;
				phandle = <0xa5>;
			};
		};

		uart0 {

			uart0-xfer {
				rockchip,pins = <0x00 0x10 0x03 0xbf 0x00 0x11 0x03 0xbf>;
				phandle = <0x26>;
			};
		};

		uart1 {

			uart1m0-xfer {
				rockchip,pins = <0x02 0x0b 0x02 0xbf 0x02 0x0c 0x02 0xbf>;
				phandle = <0x91>;
			};

			uart1m0-ctsn {
				rockchip,pins = <0x02 0x0e 0x02 0xbd>;
				phandle = <0x92>;
			};

			uart1m0-rtsn {
				rockchip,pins = <0x02 0x0d 0x02 0xbd>;
				phandle = <0x93>;
			};
		};

		uart2 {

			uart2m0-xfer {
				rockchip,pins = <0x00 0x18 0x01 0xbf 0x00 0x19 0x01 0xbf>;
				phandle = <0x99>;
			};
		};

		uart3 {

			uart3m0-xfer {
				rockchip,pins = <0x01 0x00 0x02 0xbf 0x01 0x01 0x02 0xbf>;
				phandle = <0x9a>;
			};
		};

		uart4 {

			uart4m0-xfer {
				rockchip,pins = <0x01 0x04 0x02 0xbf 0x01 0x06 0x02 0xbf>;
				phandle = <0x9b>;
			};
		};

		uart5 {

			uart5m0-xfer {
				rockchip,pins = <0x02 0x01 0x03 0xbf 0x02 0x02 0x03 0xbf>;
				phandle = <0x9c>;
			};
		};

		uart6 {

			uart6m0-xfer {
				rockchip,pins = <0x02 0x03 0x03 0xbf 0x02 0x04 0x03 0xbf>;
				phandle = <0x9d>;
			};
		};

		uart7 {

			uart7m0-xfer {
				rockchip,pins = <0x02 0x05 0x03 0xbf 0x02 0x06 0x03 0xbf>;
				phandle = <0x9e>;
			};
		};

		uart8 {

			uart8m0-xfer {
				rockchip,pins = <0x02 0x16 0x02 0xbf 0x02 0x15 0x03 0xbf>;
				phandle = <0x9f>;
			};

			uart8m1-xfer {
				rockchip,pins = <0x03 0x00 0x04 0xbf 0x02 0x1f 0x04 0xbf>;
				phandle = <0x6e>;
			};
		};

		uart9 {

			uart9m0-xfer {
				rockchip,pins = <0x02 0x07 0x03 0xbf 0x02 0x08 0x03 0xbf>;
				phandle = <0xa0>;
			};

			uart9m1-xfer {
				rockchip,pins = <0x04 0x16 0x04 0xbf 0x04 0x15 0x04 0xbf>;
				phandle = <0x6d>;
			};
		};

		vop {
		};

		spi0-hs {
		};

		spi1-hs {
		};

		spi2-hs {
		};

		spi3-hs {
		};

		gmac-txd-level3 {
		};

		gmac-txc-level2 {
		};

		sdio-pwrseq {

			wifi-enable-h {
				rockchip,pins = <0x02 0x09 0x00 0xbd>;
				phandle = <0xcd>;
			};
		};

		bt {

			bt-enable-h {
				rockchip,pins = <0x02 0x11 0x00 0xbd>;
				phandle = <0x98>;
			};

			bt-host-wake-l {
				rockchip,pins = <0x02 0x10 0x00 0xc5>;
				phandle = <0x96>;
			};

			bt-wake-l {
				rockchip,pins = <0x02 0x0f 0x00 0xbd>;
				phandle = <0x97>;
			};
		};

		usb {

			vcc5v0-host-en {
				rockchip,pins = <0x00 0x06 0x00 0xbd>;
				phandle = <0xc8>;
			};

			vcc5v0-otg-en {
				rockchip,pins = <0x00 0x05 0x00 0xbd>;
				phandle = <0xc9>;
			};
		};

		pcie {

			pcie-enable-h {
				rockchip,pins = <0x00 0x14 0x00 0xbd>;
				phandle = <0xca>;
			};

			pcie-reset-h {
				rockchip,pins = <0x01 0x0a 0x00 0xbd>;
				phandle = <0x61>;
			};
		};

		leds {

			led-power {
				rockchip,pins = <0x00 0x1b 0x00 0xbd>;
				phandle = <0xcb>;
			};

			led-user {
				rockchip,pins = <0x00 0x1c 0x00 0xbd>;
				phandle = <0xcc>;
			};
		};

		headphone {

			hp-det {
				rockchip,pins = <0x02 0x1a 0x00 0xbf>;
				phandle = <0xcf>;
			};
		};
	};

	chosen {
		stdout-path = "serial2:1500000n8";
	};

	vcc5v0_in {
		compatible = "regulator-fixed";
		regulator-name = "vcc5v0_in";
		regulator-always-on;
		regulator-boot-on;
		regulator-min-microvolt = <0x4c4b40>;
		regulator-max-microvolt = <0x4c4b40>;
		phandle = <0xc7>;
	};

	external-gmac1-clock {
		compatible = "fixed-clock";
		clock-frequency = <0x7735940>;
		clock-output-names = "gmac1_clkin";
		#clock-cells = <0x00>;
		phandle = <0x4d>;
	};

	hdmi-con {
		compatible = "hdmi-connector";
		type = "a";

		port {

			endpoint {
				remote-endpoint = <0xc6>;
				phandle = <0x5f>;
			};
		};
	};

	vcc3v3-sys {
		compatible = "regulator-fixed";
		regulator-name = "vcc3v3_sys";
		regulator-always-on;
		regulator-boot-on;
		regulator-min-microvolt = <0x325aa0>;
		regulator-max-microvolt = <0x325aa0>;
		vin-supply = <0x20>;
		phandle = <0x24>;
	};

	vcc5v0_sys {
		compatible = "regulator-fixed";
		regulator-name = "vcc5v0_sys";
		regulator-always-on;
		regulator-boot-on;
		regulator-min-microvolt = <0x4c4b40>;
		regulator-max-microvolt = <0x4c4b40>;
		vin-supply = <0xc7>;
		phandle = <0x20>;
	};

	vcc5v0-host-regulator {
		compatible = "regulator-fixed";
		regulator-name = "vcc5v0_host";
		enable-active-high;
		gpio = <0x21 0x06 0x00>;
		pinctrl-names = "default";
		pinctrl-0 = <0xc8>;
		regulator-always-on;
		regulator-min-microvolt = <0x4c4b40>;
		regulator-max-microvolt = <0x4c4b40>;
		vin-supply = <0x20>;
		phandle = <0xb8>;
	};

	vcc5v0-otg-regulator {
		compatible = "regulator-fixed";
		regulator-name = "vcc5v0_otg";
		enable-active-high;
		gpio = <0x21 0x05 0x00>;
		pinctrl-names = "default";
		pinctrl-0 = <0xc9>;
		regulator-always-on;
		regulator-min-microvolt = <0x4c4b40>;
		regulator-max-microvolt = <0x4c4b40>;
		vin-supply = <0x20>;
		phandle = <0xb9>;
	};

	vcc3v3-pcie-p-regulator {
		compatible = "regulator-fixed";
		enable-active-high;
		gpio = <0x21 0x14 0x00>;
		pinctrl-names = "default";
		pinctrl-0 = <0xca>;
		regulator-name = "vcc3v3_pcie_p";
		regulator-min-microvolt = <0x325aa0>;
		regulator-max-microvolt = <0x325aa0>;
		vin-supply = <0x1b>;
		phandle = <0x63>;
	};

	leds {
		compatible = "gpio-leds";

		power {
			label = "firefly:blue:power";
			linux,default-trigger = "ir-power-click";
			default-state = "on";
			gpios = <0x21 0x1b 0x00>;
			pinctrl-names = "default";
			pinctrl-0 = <0xcb>;
		};

		user {
			label = "firefly:yellow:user";
			linux,default-trigger = "ir-user-click";
			default-state = "off";
			gpios = <0x21 0x1c 0x00>;
			pinctrl-names = "default";
			pinctrl-0 = <0xcc>;
		};
	};

	sdio-pwrseq {
		status = "okay";
		compatible = "mmc-pwrseq-simple";
		clocks = <0x94 0x01>;
		clock-names = "ext_clock";
		pinctrl-names = "default";
		pinctrl-0 = <0xcd>;
		reset-gpios = <0x95 0x09 0x01>;
		phandle = <0x69>;
	};

	rk809-sound {
		compatible = "simple-audio-card";
		simple-audio-card,format = "i2s";
		simple-audio-card,name = "Analog RK809";
		simple-audio-card,mclk-fs = <0x100>;

		simple-audio-card,cpu {
			sound-dai = <0xce>;
		};

		simple-audio-card,codec {
			sound-dai = <0x94>;
		};
	};

	rk-headset {
		compatible = "rockchip_headset";
		headset_gpio = <0x95 0x1a 0x00>;
		pinctrl-names = "default";
		pinctrl-0 = <0xcf>;
		io-channels = <0xd0 0x02>;
	};
};
